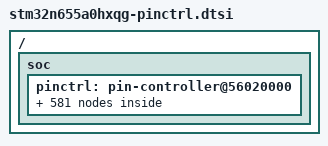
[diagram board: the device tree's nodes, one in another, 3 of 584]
/*
 * NOTE: Autogenerated file using genpinctrl.py
 *
 * SPDX-License-Identifier: Apache-2.0
 */

#include <zephyr/dt-bindings/pinctrl/stm32-pinctrl.h>

/ {
	soc {
		pinctrl: pin-controller@56020000 {

			/* ADC_IN / ADC_INN / ADC_INP */

			/omit-if-no-ref/ adc1_inn1_pa0: adc1_inn1_pa0 {
				pinmux = <STM32_PINMUX('A', 0, ANALOG)>;
			};

			/omit-if-no-ref/ adc1_inp0_pa0: adc1_inp0_pa0 {
				pinmux = <STM32_PINMUX('A', 0, ANALOG)>;
			};

			/omit-if-no-ref/ adc1_inp1_pa1: adc1_inp1_pa1 {
				pinmux = <STM32_PINMUX('A', 1, ANALOG)>;
			};

			/omit-if-no-ref/ adc1_inp14_pa2: adc1_inp14_pa2 {
				pinmux = <STM32_PINMUX('A', 2, ANALOG)>;
			};

			/omit-if-no-ref/ adc1_inp3_pa6: adc1_inp3_pa6 {
				pinmux = <STM32_PINMUX('A', 6, ANALOG)>;
			};

			/omit-if-no-ref/ adc1_inp5_pa8: adc1_inp5_pa8 {
				pinmux = <STM32_PINMUX('A', 8, ANALOG)>;
			};

			/omit-if-no-ref/ adc1_inp10_pa9: adc1_inp10_pa9 {
				pinmux = <STM32_PINMUX('A', 9, ANALOG)>;
			};

			/omit-if-no-ref/ adc1_inn10_pa10: adc1_inn10_pa10 {
				pinmux = <STM32_PINMUX('A', 10, ANALOG)>;
			};

			/omit-if-no-ref/ adc1_inp11_pa10: adc1_inp11_pa10 {
				pinmux = <STM32_PINMUX('A', 10, ANALOG)>;
			};

			/omit-if-no-ref/ adc1_inn11_pa11: adc1_inn11_pa11 {
				pinmux = <STM32_PINMUX('A', 11, ANALOG)>;
			};

			/omit-if-no-ref/ adc1_inp12_pa11: adc1_inp12_pa11 {
				pinmux = <STM32_PINMUX('A', 11, ANALOG)>;
			};

			/omit-if-no-ref/ adc1_inn12_pa12: adc1_inn12_pa12 {
				pinmux = <STM32_PINMUX('A', 12, ANALOG)>;
			};

			/omit-if-no-ref/ adc1_inp13_pa12: adc1_inp13_pa12 {
				pinmux = <STM32_PINMUX('A', 12, ANALOG)>;
			};

			/omit-if-no-ref/ adc1_inn4_pb10: adc1_inn4_pb10 {
				pinmux = <STM32_PINMUX('B', 10, ANALOG)>;
			};

			/omit-if-no-ref/ adc1_inp8_pb10: adc1_inp8_pb10 {
				pinmux = <STM32_PINMUX('B', 10, ANALOG)>;
			};

			/omit-if-no-ref/ adc1_inp4_pb11: adc1_inp4_pb11 {
				pinmux = <STM32_PINMUX('B', 11, ANALOG)>;
			};

			/omit-if-no-ref/ adc1_inp18_pf4: adc1_inp18_pf4 {
				pinmux = <STM32_PINMUX('F', 4, ANALOG)>;
			};

			/omit-if-no-ref/ adc1_inn5_pf7: adc1_inn5_pf7 {
				pinmux = <STM32_PINMUX('F', 7, ANALOG)>;
			};

			/omit-if-no-ref/ adc1_inp9_pf7: adc1_inp9_pf7 {
				pinmux = <STM32_PINMUX('F', 7, ANALOG)>;
			};

			/omit-if-no-ref/ adc1_inp2_pf11: adc1_inp2_pf11 {
				pinmux = <STM32_PINMUX('F', 11, ANALOG)>;
			};

			/omit-if-no-ref/ adc1_inn2_pf12: adc1_inn2_pf12 {
				pinmux = <STM32_PINMUX('F', 12, ANALOG)>;
			};

			/omit-if-no-ref/ adc1_inp6_pf12: adc1_inp6_pf12 {
				pinmux = <STM32_PINMUX('F', 12, ANALOG)>;
			};

			/omit-if-no-ref/ adc2_inn1_pa0: adc2_inn1_pa0 {
				pinmux = <STM32_PINMUX('A', 0, ANALOG)>;
			};

			/omit-if-no-ref/ adc2_inp0_pa0: adc2_inp0_pa0 {
				pinmux = <STM32_PINMUX('A', 0, ANALOG)>;
			};

			/omit-if-no-ref/ adc2_inp1_pa1: adc2_inp1_pa1 {
				pinmux = <STM32_PINMUX('A', 1, ANALOG)>;
			};

			/omit-if-no-ref/ adc2_inp14_pa2: adc2_inp14_pa2 {
				pinmux = <STM32_PINMUX('A', 2, ANALOG)>;
			};

			/omit-if-no-ref/ adc2_inp18_pa5: adc2_inp18_pa5 {
				pinmux = <STM32_PINMUX('A', 5, ANALOG)>;
			};

			/omit-if-no-ref/ adc2_inp3_pa6: adc2_inp3_pa6 {
				pinmux = <STM32_PINMUX('A', 6, ANALOG)>;
			};

			/omit-if-no-ref/ adc2_inp5_pa8: adc2_inp5_pa8 {
				pinmux = <STM32_PINMUX('A', 8, ANALOG)>;
			};

			/omit-if-no-ref/ adc2_inp10_pa9: adc2_inp10_pa9 {
				pinmux = <STM32_PINMUX('A', 9, ANALOG)>;
			};

			/omit-if-no-ref/ adc2_inn10_pa10: adc2_inn10_pa10 {
				pinmux = <STM32_PINMUX('A', 10, ANALOG)>;
			};

			/omit-if-no-ref/ adc2_inp11_pa10: adc2_inp11_pa10 {
				pinmux = <STM32_PINMUX('A', 10, ANALOG)>;
			};

			/omit-if-no-ref/ adc2_inn11_pa11: adc2_inn11_pa11 {
				pinmux = <STM32_PINMUX('A', 11, ANALOG)>;
			};

			/omit-if-no-ref/ adc2_inp12_pa11: adc2_inp12_pa11 {
				pinmux = <STM32_PINMUX('A', 11, ANALOG)>;
			};

			/omit-if-no-ref/ adc2_inn12_pa12: adc2_inn12_pa12 {
				pinmux = <STM32_PINMUX('A', 12, ANALOG)>;
			};

			/omit-if-no-ref/ adc2_inp13_pa12: adc2_inp13_pa12 {
				pinmux = <STM32_PINMUX('A', 12, ANALOG)>;
			};

			/omit-if-no-ref/ adc2_inn4_pb10: adc2_inn4_pb10 {
				pinmux = <STM32_PINMUX('B', 10, ANALOG)>;
			};

			/omit-if-no-ref/ adc2_inp8_pb10: adc2_inp8_pb10 {
				pinmux = <STM32_PINMUX('B', 10, ANALOG)>;
			};

			/omit-if-no-ref/ adc2_inp4_pb11: adc2_inp4_pb11 {
				pinmux = <STM32_PINMUX('B', 11, ANALOG)>;
			};

			/omit-if-no-ref/ adc2_inn5_pf7: adc2_inn5_pf7 {
				pinmux = <STM32_PINMUX('F', 7, ANALOG)>;
			};

			/omit-if-no-ref/ adc2_inp9_pf7: adc2_inp9_pf7 {
				pinmux = <STM32_PINMUX('F', 7, ANALOG)>;
			};

			/omit-if-no-ref/ adc2_inp2_pf13: adc2_inp2_pf13 {
				pinmux = <STM32_PINMUX('F', 13, ANALOG)>;
			};

			/omit-if-no-ref/ adc2_inn2_pf14: adc2_inn2_pf14 {
				pinmux = <STM32_PINMUX('F', 14, ANALOG)>;
			};

			/omit-if-no-ref/ adc2_inp6_pf14: adc2_inp6_pf14 {
				pinmux = <STM32_PINMUX('F', 14, ANALOG)>;
			};

			/* Analog */

			/omit-if-no-ref/ analog_pa0: analog_pa0 {
				pinmux = <STM32_PINMUX('A', 0, ANALOG)>;
			};

			/omit-if-no-ref/ analog_pa1: analog_pa1 {
				pinmux = <STM32_PINMUX('A', 1, ANALOG)>;
			};

			/omit-if-no-ref/ analog_pa2: analog_pa2 {
				pinmux = <STM32_PINMUX('A', 2, ANALOG)>;
			};

			/omit-if-no-ref/ analog_pa5: analog_pa5 {
				pinmux = <STM32_PINMUX('A', 5, ANALOG)>;
			};

			/omit-if-no-ref/ analog_pa6: analog_pa6 {
				pinmux = <STM32_PINMUX('A', 6, ANALOG)>;
			};

			/omit-if-no-ref/ analog_pa7: analog_pa7 {
				pinmux = <STM32_PINMUX('A', 7, ANALOG)>;
			};

			/omit-if-no-ref/ analog_pa8: analog_pa8 {
				pinmux = <STM32_PINMUX('A', 8, ANALOG)>;
			};

			/omit-if-no-ref/ analog_pa9: analog_pa9 {
				pinmux = <STM32_PINMUX('A', 9, ANALOG)>;
			};

			/omit-if-no-ref/ analog_pa10: analog_pa10 {
				pinmux = <STM32_PINMUX('A', 10, ANALOG)>;
			};

			/omit-if-no-ref/ analog_pa11: analog_pa11 {
				pinmux = <STM32_PINMUX('A', 11, ANALOG)>;
			};

			/omit-if-no-ref/ analog_pa12: analog_pa12 {
				pinmux = <STM32_PINMUX('A', 12, ANALOG)>;
			};

			/omit-if-no-ref/ analog_pa13: analog_pa13 {
				pinmux = <STM32_PINMUX('A', 13, ANALOG)>;
			};

			/omit-if-no-ref/ analog_pa14: analog_pa14 {
				pinmux = <STM32_PINMUX('A', 14, ANALOG)>;
			};

			/omit-if-no-ref/ analog_pa15: analog_pa15 {
				pinmux = <STM32_PINMUX('A', 15, ANALOG)>;
			};

			/omit-if-no-ref/ analog_pb4: analog_pb4 {
				pinmux = <STM32_PINMUX('B', 4, ANALOG)>;
			};

			/omit-if-no-ref/ analog_pb5: analog_pb5 {
				pinmux = <STM32_PINMUX('B', 5, ANALOG)>;
			};

			/omit-if-no-ref/ analog_pb6: analog_pb6 {
				pinmux = <STM32_PINMUX('B', 6, ANALOG)>;
			};

			/omit-if-no-ref/ analog_pb7: analog_pb7 {
				pinmux = <STM32_PINMUX('B', 7, ANALOG)>;
			};

			/omit-if-no-ref/ analog_pb8: analog_pb8 {
				pinmux = <STM32_PINMUX('B', 8, ANALOG)>;
			};

			/omit-if-no-ref/ analog_pb10: analog_pb10 {
				pinmux = <STM32_PINMUX('B', 10, ANALOG)>;
			};

			/omit-if-no-ref/ analog_pb11: analog_pb11 {
				pinmux = <STM32_PINMUX('B', 11, ANALOG)>;
			};

			/omit-if-no-ref/ analog_pb12: analog_pb12 {
				pinmux = <STM32_PINMUX('B', 12, ANALOG)>;
			};

			/omit-if-no-ref/ analog_pc0: analog_pc0 {
				pinmux = <STM32_PINMUX('C', 0, ANALOG)>;
			};

			/omit-if-no-ref/ analog_pc1: analog_pc1 {
				pinmux = <STM32_PINMUX('C', 1, ANALOG)>;
			};

			/omit-if-no-ref/ analog_pc2: analog_pc2 {
				pinmux = <STM32_PINMUX('C', 2, ANALOG)>;
			};

			/omit-if-no-ref/ analog_pc3: analog_pc3 {
				pinmux = <STM32_PINMUX('C', 3, ANALOG)>;
			};

			/omit-if-no-ref/ analog_pc4: analog_pc4 {
				pinmux = <STM32_PINMUX('C', 4, ANALOG)>;
			};

			/omit-if-no-ref/ analog_pc5: analog_pc5 {
				pinmux = <STM32_PINMUX('C', 5, ANALOG)>;
			};

			/omit-if-no-ref/ analog_pc6: analog_pc6 {
				pinmux = <STM32_PINMUX('C', 6, ANALOG)>;
			};

			/omit-if-no-ref/ analog_pc7: analog_pc7 {
				pinmux = <STM32_PINMUX('C', 7, ANALOG)>;
			};

			/omit-if-no-ref/ analog_pc8: analog_pc8 {
				pinmux = <STM32_PINMUX('C', 8, ANALOG)>;
			};

			/omit-if-no-ref/ analog_pc9: analog_pc9 {
				pinmux = <STM32_PINMUX('C', 9, ANALOG)>;
			};

			/omit-if-no-ref/ analog_pc10: analog_pc10 {
				pinmux = <STM32_PINMUX('C', 10, ANALOG)>;
			};

			/omit-if-no-ref/ analog_pc11: analog_pc11 {
				pinmux = <STM32_PINMUX('C', 11, ANALOG)>;
			};

			/omit-if-no-ref/ analog_pc12: analog_pc12 {
				pinmux = <STM32_PINMUX('C', 12, ANALOG)>;
			};

			/omit-if-no-ref/ analog_pc13: analog_pc13 {
				pinmux = <STM32_PINMUX('C', 13, ANALOG)>;
			};

			/omit-if-no-ref/ analog_pc14: analog_pc14 {
				pinmux = <STM32_PINMUX('C', 14, ANALOG)>;
			};

			/omit-if-no-ref/ analog_pc15: analog_pc15 {
				pinmux = <STM32_PINMUX('C', 15, ANALOG)>;
			};

			/omit-if-no-ref/ analog_pd8: analog_pd8 {
				pinmux = <STM32_PINMUX('D', 8, ANALOG)>;
			};

			/omit-if-no-ref/ analog_pd11: analog_pd11 {
				pinmux = <STM32_PINMUX('D', 11, ANALOG)>;
			};

			/omit-if-no-ref/ analog_pe0: analog_pe0 {
				pinmux = <STM32_PINMUX('E', 0, ANALOG)>;
			};

			/omit-if-no-ref/ analog_pe1: analog_pe1 {
				pinmux = <STM32_PINMUX('E', 1, ANALOG)>;
			};

			/omit-if-no-ref/ analog_pe3: analog_pe3 {
				pinmux = <STM32_PINMUX('E', 3, ANALOG)>;
			};

			/omit-if-no-ref/ analog_pe4: analog_pe4 {
				pinmux = <STM32_PINMUX('E', 4, ANALOG)>;
			};

			/omit-if-no-ref/ analog_pe5: analog_pe5 {
				pinmux = <STM32_PINMUX('E', 5, ANALOG)>;
			};

			/omit-if-no-ref/ analog_pe6: analog_pe6 {
				pinmux = <STM32_PINMUX('E', 6, ANALOG)>;
			};

			/omit-if-no-ref/ analog_pe7: analog_pe7 {
				pinmux = <STM32_PINMUX('E', 7, ANALOG)>;
			};

			/omit-if-no-ref/ analog_pe8: analog_pe8 {
				pinmux = <STM32_PINMUX('E', 8, ANALOG)>;
			};

			/omit-if-no-ref/ analog_pe9: analog_pe9 {
				pinmux = <STM32_PINMUX('E', 9, ANALOG)>;
			};

			/omit-if-no-ref/ analog_pe10: analog_pe10 {
				pinmux = <STM32_PINMUX('E', 10, ANALOG)>;
			};

			/omit-if-no-ref/ analog_pe13: analog_pe13 {
				pinmux = <STM32_PINMUX('E', 13, ANALOG)>;
			};

			/omit-if-no-ref/ analog_pf2: analog_pf2 {
				pinmux = <STM32_PINMUX('F', 2, ANALOG)>;
			};

			/omit-if-no-ref/ analog_pf4: analog_pf4 {
				pinmux = <STM32_PINMUX('F', 4, ANALOG)>;
			};

			/omit-if-no-ref/ analog_pf5: analog_pf5 {
				pinmux = <STM32_PINMUX('F', 5, ANALOG)>;
			};

			/omit-if-no-ref/ analog_pf7: analog_pf7 {
				pinmux = <STM32_PINMUX('F', 7, ANALOG)>;
			};

			/omit-if-no-ref/ analog_pf8: analog_pf8 {
				pinmux = <STM32_PINMUX('F', 8, ANALOG)>;
			};

			/omit-if-no-ref/ analog_pf10: analog_pf10 {
				pinmux = <STM32_PINMUX('F', 10, ANALOG)>;
			};

			/omit-if-no-ref/ analog_pf11: analog_pf11 {
				pinmux = <STM32_PINMUX('F', 11, ANALOG)>;
			};

			/omit-if-no-ref/ analog_pf12: analog_pf12 {
				pinmux = <STM32_PINMUX('F', 12, ANALOG)>;
			};

			/omit-if-no-ref/ analog_pf13: analog_pf13 {
				pinmux = <STM32_PINMUX('F', 13, ANALOG)>;
			};

			/omit-if-no-ref/ analog_pf14: analog_pf14 {
				pinmux = <STM32_PINMUX('F', 14, ANALOG)>;
			};

			/omit-if-no-ref/ analog_pf15: analog_pf15 {
				pinmux = <STM32_PINMUX('F', 15, ANALOG)>;
			};

			/omit-if-no-ref/ analog_pg2: analog_pg2 {
				pinmux = <STM32_PINMUX('G', 2, ANALOG)>;
			};

			/omit-if-no-ref/ analog_pg10: analog_pg10 {
				pinmux = <STM32_PINMUX('G', 10, ANALOG)>;
			};

			/omit-if-no-ref/ analog_pg13: analog_pg13 {
				pinmux = <STM32_PINMUX('G', 13, ANALOG)>;
			};

			/omit-if-no-ref/ analog_ph0: analog_ph0 {
				pinmux = <STM32_PINMUX('H', 0, ANALOG)>;
			};

			/omit-if-no-ref/ analog_ph1: analog_ph1 {
				pinmux = <STM32_PINMUX('H', 1, ANALOG)>;
			};

			/omit-if-no-ref/ analog_ph2: analog_ph2 {
				pinmux = <STM32_PINMUX('H', 2, ANALOG)>;
			};

			/omit-if-no-ref/ analog_ph9: analog_ph9 {
				pinmux = <STM32_PINMUX('H', 9, ANALOG)>;
			};

			/omit-if-no-ref/ analog_pn0: analog_pn0 {
				pinmux = <STM32_PINMUX('N', 0, ANALOG)>;
			};

			/omit-if-no-ref/ analog_pn1: analog_pn1 {
				pinmux = <STM32_PINMUX('N', 1, ANALOG)>;
			};

			/omit-if-no-ref/ analog_pn2: analog_pn2 {
				pinmux = <STM32_PINMUX('N', 2, ANALOG)>;
			};

			/omit-if-no-ref/ analog_pn3: analog_pn3 {
				pinmux = <STM32_PINMUX('N', 3, ANALOG)>;
			};

			/omit-if-no-ref/ analog_pn4: analog_pn4 {
				pinmux = <STM32_PINMUX('N', 4, ANALOG)>;
			};

			/omit-if-no-ref/ analog_pn5: analog_pn5 {
				pinmux = <STM32_PINMUX('N', 5, ANALOG)>;
			};

			/omit-if-no-ref/ analog_pn6: analog_pn6 {
				pinmux = <STM32_PINMUX('N', 6, ANALOG)>;
			};

			/omit-if-no-ref/ analog_pn7: analog_pn7 {
				pinmux = <STM32_PINMUX('N', 7, ANALOG)>;
			};

			/omit-if-no-ref/ analog_pn8: analog_pn8 {
				pinmux = <STM32_PINMUX('N', 8, ANALOG)>;
			};

			/omit-if-no-ref/ analog_pn9: analog_pn9 {
				pinmux = <STM32_PINMUX('N', 9, ANALOG)>;
			};

			/omit-if-no-ref/ analog_pn10: analog_pn10 {
				pinmux = <STM32_PINMUX('N', 10, ANALOG)>;
			};

			/omit-if-no-ref/ analog_pn11: analog_pn11 {
				pinmux = <STM32_PINMUX('N', 11, ANALOG)>;
			};

			/omit-if-no-ref/ analog_pn12: analog_pn12 {
				pinmux = <STM32_PINMUX('N', 12, ANALOG)>;
			};

			/omit-if-no-ref/ analog_po0: analog_po0 {
				pinmux = <STM32_PINMUX('O', 0, ANALOG)>;
			};

			/omit-if-no-ref/ analog_po1: analog_po1 {
				pinmux = <STM32_PINMUX('O', 1, ANALOG)>;
			};

			/omit-if-no-ref/ analog_po2: analog_po2 {
				pinmux = <STM32_PINMUX('O', 2, ANALOG)>;
			};

			/omit-if-no-ref/ analog_po3: analog_po3 {
				pinmux = <STM32_PINMUX('O', 3, ANALOG)>;
			};

			/omit-if-no-ref/ analog_po4: analog_po4 {
				pinmux = <STM32_PINMUX('O', 4, ANALOG)>;
			};

			/omit-if-no-ref/ analog_po5: analog_po5 {
				pinmux = <STM32_PINMUX('O', 5, ANALOG)>;
			};

			/omit-if-no-ref/ analog_pp0: analog_pp0 {
				pinmux = <STM32_PINMUX('P', 0, ANALOG)>;
			};

			/omit-if-no-ref/ analog_pp1: analog_pp1 {
				pinmux = <STM32_PINMUX('P', 1, ANALOG)>;
			};

			/omit-if-no-ref/ analog_pp2: analog_pp2 {
				pinmux = <STM32_PINMUX('P', 2, ANALOG)>;
			};

			/omit-if-no-ref/ analog_pp3: analog_pp3 {
				pinmux = <STM32_PINMUX('P', 3, ANALOG)>;
			};

			/omit-if-no-ref/ analog_pp4: analog_pp4 {
				pinmux = <STM32_PINMUX('P', 4, ANALOG)>;
			};

			/omit-if-no-ref/ analog_pp5: analog_pp5 {
				pinmux = <STM32_PINMUX('P', 5, ANALOG)>;
			};

			/omit-if-no-ref/ analog_pp6: analog_pp6 {
				pinmux = <STM32_PINMUX('P', 6, ANALOG)>;
			};

			/omit-if-no-ref/ analog_pp7: analog_pp7 {
				pinmux = <STM32_PINMUX('P', 7, ANALOG)>;
			};

			/omit-if-no-ref/ analog_pp8: analog_pp8 {
				pinmux = <STM32_PINMUX('P', 8, ANALOG)>;
			};

			/omit-if-no-ref/ analog_pp9: analog_pp9 {
				pinmux = <STM32_PINMUX('P', 9, ANALOG)>;
			};

			/omit-if-no-ref/ analog_pp10: analog_pp10 {
				pinmux = <STM32_PINMUX('P', 10, ANALOG)>;
			};

			/omit-if-no-ref/ analog_pp11: analog_pp11 {
				pinmux = <STM32_PINMUX('P', 11, ANALOG)>;
			};

			/omit-if-no-ref/ analog_pp12: analog_pp12 {
				pinmux = <STM32_PINMUX('P', 12, ANALOG)>;
			};

			/omit-if-no-ref/ analog_pp13: analog_pp13 {
				pinmux = <STM32_PINMUX('P', 13, ANALOG)>;
			};

			/omit-if-no-ref/ analog_pp14: analog_pp14 {
				pinmux = <STM32_PINMUX('P', 14, ANALOG)>;
			};

			/omit-if-no-ref/ analog_pp15: analog_pp15 {
				pinmux = <STM32_PINMUX('P', 15, ANALOG)>;
			};

			/* DCMI */

			/omit-if-no-ref/ dcmi_d0_pa1: dcmi_d0_pa1 {
				pinmux = <STM32_PINMUX('A', 1, AF9)>;
				slew-rate = "very-high-speed";
			};

			/omit-if-no-ref/ dcmi_d8_pa5: dcmi_d8_pa5 {
				pinmux = <STM32_PINMUX('A', 5, AF9)>;
				slew-rate = "very-high-speed";
			};

			/omit-if-no-ref/ dcmi_pixclk_pa6: dcmi_pixclk_pa6 {
				pinmux = <STM32_PINMUX('A', 6, AF9)>;
				slew-rate = "very-high-speed";
			};

			/omit-if-no-ref/ dcmi_d0_pa9: dcmi_d0_pa9 {
				pinmux = <STM32_PINMUX('A', 9, AF9)>;
				slew-rate = "very-high-speed";
			};

			/omit-if-no-ref/ dcmi_d1_pa10: dcmi_d1_pa10 {
				pinmux = <STM32_PINMUX('A', 10, AF9)>;
				slew-rate = "very-high-speed";
			};

			/omit-if-no-ref/ dcmi_vsync_pb4: dcmi_vsync_pb4 {
				pinmux = <STM32_PINMUX('B', 4, AF9)>;
				slew-rate = "very-high-speed";
			};

			/omit-if-no-ref/ dcmi_d10_pb5: dcmi_d10_pb5 {
				pinmux = <STM32_PINMUX('B', 5, AF9)>;
				slew-rate = "very-high-speed";
			};

			/omit-if-no-ref/ dcmi_d6_pb6: dcmi_d6_pb6 {
				pinmux = <STM32_PINMUX('B', 6, AF9)>;
				slew-rate = "very-high-speed";
			};

			/omit-if-no-ref/ dcmi_d7_pb7: dcmi_d7_pb7 {
				pinmux = <STM32_PINMUX('B', 7, AF9)>;
				slew-rate = "very-high-speed";
			};

			/omit-if-no-ref/ dcmi_vsync_pb8: dcmi_vsync_pb8 {
				pinmux = <STM32_PINMUX('B', 8, AF9)>;
				slew-rate = "very-high-speed";
			};

			/omit-if-no-ref/ dcmi_hsync_pc0: dcmi_hsync_pc0 {
				pinmux = <STM32_PINMUX('C', 0, AF9)>;
				slew-rate = "very-high-speed";
			};

			/omit-if-no-ref/ dcmi_d7_pc1: dcmi_d7_pc1 {
				pinmux = <STM32_PINMUX('C', 1, AF9)>;
				slew-rate = "very-high-speed";
			};

			/omit-if-no-ref/ dcmi_d13_pc2: dcmi_d13_pc2 {
				pinmux = <STM32_PINMUX('C', 2, AF9)>;
				slew-rate = "very-high-speed";
			};

			/omit-if-no-ref/ dcmi_d2_pc3: dcmi_d2_pc3 {
				pinmux = <STM32_PINMUX('C', 3, AF9)>;
				slew-rate = "very-high-speed";
			};

			/omit-if-no-ref/ dcmi_d2_pc5: dcmi_d2_pc5 {
				pinmux = <STM32_PINMUX('C', 5, AF9)>;
				slew-rate = "very-high-speed";
			};

			/omit-if-no-ref/ dcmi_d1_pc6: dcmi_d1_pc6 {
				pinmux = <STM32_PINMUX('C', 6, AF9)>;
				slew-rate = "very-high-speed";
			};

			/omit-if-no-ref/ dcmi_d1_pc7: dcmi_d1_pc7 {
				pinmux = <STM32_PINMUX('C', 7, AF9)>;
				slew-rate = "very-high-speed";
			};

			/omit-if-no-ref/ dcmi_d2_pc8: dcmi_d2_pc8 {
				pinmux = <STM32_PINMUX('C', 8, AF9)>;
				slew-rate = "very-high-speed";
			};

			/omit-if-no-ref/ dcmi_d3_pc9: dcmi_d3_pc9 {
				pinmux = <STM32_PINMUX('C', 9, AF9)>;
				slew-rate = "very-high-speed";
			};

			/omit-if-no-ref/ dcmi_d4_pc11: dcmi_d4_pc11 {
				pinmux = <STM32_PINMUX('C', 11, AF9)>;
				slew-rate = "very-high-speed";
			};

			/omit-if-no-ref/ dcmi_d9_pc12: dcmi_d9_pc12 {
				pinmux = <STM32_PINMUX('C', 12, AF9)>;
				slew-rate = "very-high-speed";
			};

			/omit-if-no-ref/ dcmi_d11_pd8: dcmi_d11_pd8 {
				pinmux = <STM32_PINMUX('D', 8, AF9)>;
				slew-rate = "very-high-speed";
			};

			/omit-if-no-ref/ dcmi_d2_pe0: dcmi_d2_pe0 {
				pinmux = <STM32_PINMUX('E', 0, AF9)>;
				slew-rate = "very-high-speed";
			};

			/omit-if-no-ref/ dcmi_d8_pe1: dcmi_d8_pe1 {
				pinmux = <STM32_PINMUX('E', 1, AF9)>;
				slew-rate = "very-high-speed";
			};

			/omit-if-no-ref/ dcmi_d5_pe4: dcmi_d5_pe4 {
				pinmux = <STM32_PINMUX('E', 4, AF9)>;
				slew-rate = "very-high-speed";
			};

			/omit-if-no-ref/ dcmi_d5_pe5: dcmi_d5_pe5 {
				pinmux = <STM32_PINMUX('E', 5, AF9)>;
				slew-rate = "very-high-speed";
			};

			/omit-if-no-ref/ dcmi_d1_pe6: dcmi_d1_pe6 {
				pinmux = <STM32_PINMUX('E', 6, AF10)>;
				slew-rate = "very-high-speed";
			};

			/omit-if-no-ref/ dcmi_vsync_pe6: dcmi_vsync_pe6 {
				pinmux = <STM32_PINMUX('E', 6, AF9)>;
				slew-rate = "very-high-speed";
			};

			/omit-if-no-ref/ dcmi_d4_pe8: dcmi_d4_pe8 {
				pinmux = <STM32_PINMUX('E', 8, AF9)>;
				slew-rate = "very-high-speed";
			};

			/omit-if-no-ref/ dcmi_d3_pe10: dcmi_d3_pe10 {
				pinmux = <STM32_PINMUX('E', 10, AF9)>;
				slew-rate = "very-high-speed";
			};

			/omit-if-no-ref/ dcmi_hsync_pf4: dcmi_hsync_pf4 {
				pinmux = <STM32_PINMUX('F', 4, AF9)>;
				slew-rate = "very-high-speed";
			};

			/omit-if-no-ref/ dcmi_d6_pf5: dcmi_d6_pf5 {
				pinmux = <STM32_PINMUX('F', 5, AF9)>;
				slew-rate = "very-high-speed";
			};

			/omit-if-no-ref/ dcmi_d11_pf10: dcmi_d11_pf10 {
				pinmux = <STM32_PINMUX('F', 10, AF9)>;
				slew-rate = "very-high-speed";
			};

			/omit-if-no-ref/ dcmi_d13_pf12: dcmi_d13_pf12 {
				pinmux = <STM32_PINMUX('F', 12, AF9)>;
				slew-rate = "very-high-speed";
			};

			/omit-if-no-ref/ dcmi_d10_pf13: dcmi_d10_pf13 {
				pinmux = <STM32_PINMUX('F', 13, AF9)>;
				slew-rate = "very-high-speed";
			};

			/omit-if-no-ref/ dcmi_d6_pg2: dcmi_d6_pg2 {
				pinmux = <STM32_PINMUX('G', 2, AF9)>;
				slew-rate = "very-high-speed";
			};

			/omit-if-no-ref/ dcmi_d2_pg10: dcmi_d2_pg10 {
				pinmux = <STM32_PINMUX('G', 10, AF9)>;
				slew-rate = "very-high-speed";
			};

			/omit-if-no-ref/ dcmi_d12_pg13: dcmi_d12_pg13 {
				pinmux = <STM32_PINMUX('G', 13, AF9)>;
				slew-rate = "very-high-speed";
			};

			/omit-if-no-ref/ dcmi_d11_ph2: dcmi_d11_ph2 {
				pinmux = <STM32_PINMUX('H', 2, AF9)>;
				slew-rate = "very-high-speed";
			};

			/omit-if-no-ref/ dcmi_d6_ph9: dcmi_d6_ph9 {
				pinmux = <STM32_PINMUX('H', 9, AF9)>;
				slew-rate = "very-high-speed";
			};

			/omit-if-no-ref/ dcmi_d5_pn9: dcmi_d5_pn9 {
				pinmux = <STM32_PINMUX('N', 9, AF10)>;
				slew-rate = "very-high-speed";
			};

			/* DCMIPP */

			/omit-if-no-ref/ dcmipp_d0_pa1: dcmipp_d0_pa1 {
				pinmux = <STM32_PINMUX('A', 1, AF9)>;
				slew-rate = "very-high-speed";
			};

			/omit-if-no-ref/ dcmipp_d8_pa5: dcmipp_d8_pa5 {
				pinmux = <STM32_PINMUX('A', 5, AF9)>;
				slew-rate = "very-high-speed";
			};

			/omit-if-no-ref/ dcmipp_pixclk_pa6: dcmipp_pixclk_pa6 {
				pinmux = <STM32_PINMUX('A', 6, AF9)>;
				slew-rate = "very-high-speed";
			};

			/omit-if-no-ref/ dcmipp_d0_pa9: dcmipp_d0_pa9 {
				pinmux = <STM32_PINMUX('A', 9, AF9)>;
				slew-rate = "very-high-speed";
			};

			/omit-if-no-ref/ dcmipp_d1_pa10: dcmipp_d1_pa10 {
				pinmux = <STM32_PINMUX('A', 10, AF9)>;
				slew-rate = "very-high-speed";
			};

			/omit-if-no-ref/ dcmipp_vsync_pb4: dcmipp_vsync_pb4 {
				pinmux = <STM32_PINMUX('B', 4, AF9)>;
				slew-rate = "very-high-speed";
			};

			/omit-if-no-ref/ dcmipp_d10_pb5: dcmipp_d10_pb5 {
				pinmux = <STM32_PINMUX('B', 5, AF9)>;
				slew-rate = "very-high-speed";
			};

			/omit-if-no-ref/ dcmipp_d6_pb6: dcmipp_d6_pb6 {
				pinmux = <STM32_PINMUX('B', 6, AF9)>;
				slew-rate = "very-high-speed";
			};

			/omit-if-no-ref/ dcmipp_d7_pb7: dcmipp_d7_pb7 {
				pinmux = <STM32_PINMUX('B', 7, AF9)>;
				slew-rate = "very-high-speed";
			};

			/omit-if-no-ref/ dcmipp_vsync_pb8: dcmipp_vsync_pb8 {
				pinmux = <STM32_PINMUX('B', 8, AF9)>;
				slew-rate = "very-high-speed";
			};

			/omit-if-no-ref/ dcmipp_hsync_pc0: dcmipp_hsync_pc0 {
				pinmux = <STM32_PINMUX('C', 0, AF9)>;
				slew-rate = "very-high-speed";
			};

			/omit-if-no-ref/ dcmipp_d7_pc1: dcmipp_d7_pc1 {
				pinmux = <STM32_PINMUX('C', 1, AF9)>;
				slew-rate = "very-high-speed";
			};

			/omit-if-no-ref/ dcmipp_d13_pc2: dcmipp_d13_pc2 {
				pinmux = <STM32_PINMUX('C', 2, AF9)>;
				slew-rate = "very-high-speed";
			};

			/omit-if-no-ref/ dcmipp_d2_pc3: dcmipp_d2_pc3 {
				pinmux = <STM32_PINMUX('C', 3, AF9)>;
				slew-rate = "very-high-speed";
			};

			/omit-if-no-ref/ dcmipp_d2_pc5: dcmipp_d2_pc5 {
				pinmux = <STM32_PINMUX('C', 5, AF9)>;
				slew-rate = "very-high-speed";
			};

			/omit-if-no-ref/ dcmipp_d1_pc6: dcmipp_d1_pc6 {
				pinmux = <STM32_PINMUX('C', 6, AF9)>;
				slew-rate = "very-high-speed";
			};

			/omit-if-no-ref/ dcmipp_d1_pc7: dcmipp_d1_pc7 {
				pinmux = <STM32_PINMUX('C', 7, AF9)>;
				slew-rate = "very-high-speed";
			};

			/omit-if-no-ref/ dcmipp_d2_pc8: dcmipp_d2_pc8 {
				pinmux = <STM32_PINMUX('C', 8, AF9)>;
				slew-rate = "very-high-speed";
			};

			/omit-if-no-ref/ dcmipp_d3_pc9: dcmipp_d3_pc9 {
				pinmux = <STM32_PINMUX('C', 9, AF9)>;
				slew-rate = "very-high-speed";
			};

			/omit-if-no-ref/ dcmipp_d14_pc10: dcmipp_d14_pc10 {
				pinmux = <STM32_PINMUX('C', 10, AF9)>;
				slew-rate = "very-high-speed";
			};

			/omit-if-no-ref/ dcmipp_d4_pc11: dcmipp_d4_pc11 {
				pinmux = <STM32_PINMUX('C', 11, AF9)>;
				slew-rate = "very-high-speed";
			};

			/omit-if-no-ref/ dcmipp_d9_pc12: dcmipp_d9_pc12 {
				pinmux = <STM32_PINMUX('C', 12, AF9)>;
				slew-rate = "very-high-speed";
			};

			/omit-if-no-ref/ dcmipp_d11_pd8: dcmipp_d11_pd8 {
				pinmux = <STM32_PINMUX('D', 8, AF9)>;
				slew-rate = "very-high-speed";
			};

			/omit-if-no-ref/ dcmipp_d15_pd11: dcmipp_d15_pd11 {
				pinmux = <STM32_PINMUX('D', 11, AF9)>;
				slew-rate = "very-high-speed";
			};

			/omit-if-no-ref/ dcmipp_d2_pe0: dcmipp_d2_pe0 {
				pinmux = <STM32_PINMUX('E', 0, AF9)>;
				slew-rate = "very-high-speed";
			};

			/omit-if-no-ref/ dcmipp_d8_pe1: dcmipp_d8_pe1 {
				pinmux = <STM32_PINMUX('E', 1, AF9)>;
				slew-rate = "very-high-speed";
			};

			/omit-if-no-ref/ dcmipp_d5_pe4: dcmipp_d5_pe4 {
				pinmux = <STM32_PINMUX('E', 4, AF9)>;
				slew-rate = "very-high-speed";
			};

			/omit-if-no-ref/ dcmipp_d5_pe5: dcmipp_d5_pe5 {
				pinmux = <STM32_PINMUX('E', 5, AF9)>;
				slew-rate = "very-high-speed";
			};

			/omit-if-no-ref/ dcmipp_d1_pe6: dcmipp_d1_pe6 {
				pinmux = <STM32_PINMUX('E', 6, AF10)>;
				slew-rate = "very-high-speed";
			};

			/omit-if-no-ref/ dcmipp_vsync_pe6: dcmipp_vsync_pe6 {
				pinmux = <STM32_PINMUX('E', 6, AF9)>;
				slew-rate = "very-high-speed";
			};

			/omit-if-no-ref/ dcmipp_d4_pe8: dcmipp_d4_pe8 {
				pinmux = <STM32_PINMUX('E', 8, AF9)>;
				slew-rate = "very-high-speed";
			};

			/omit-if-no-ref/ dcmipp_d3_pe10: dcmipp_d3_pe10 {
				pinmux = <STM32_PINMUX('E', 10, AF9)>;
				slew-rate = "very-high-speed";
			};

			/omit-if-no-ref/ dcmipp_hsync_pf4: dcmipp_hsync_pf4 {
				pinmux = <STM32_PINMUX('F', 4, AF9)>;
				slew-rate = "very-high-speed";
			};

			/omit-if-no-ref/ dcmipp_d6_pf5: dcmipp_d6_pf5 {
				pinmux = <STM32_PINMUX('F', 5, AF9)>;
				slew-rate = "very-high-speed";
			};

			/omit-if-no-ref/ dcmipp_d11_pf10: dcmipp_d11_pf10 {
				pinmux = <STM32_PINMUX('F', 10, AF9)>;
				slew-rate = "very-high-speed";
			};

			/omit-if-no-ref/ dcmipp_d15_pf10: dcmipp_d15_pf10 {
				pinmux = <STM32_PINMUX('F', 10, AF10)>;
				slew-rate = "very-high-speed";
			};

			/omit-if-no-ref/ dcmipp_d15_pf11: dcmipp_d15_pf11 {
				pinmux = <STM32_PINMUX('F', 11, AF9)>;
				slew-rate = "very-high-speed";
			};

			/omit-if-no-ref/ dcmipp_d13_pf12: dcmipp_d13_pf12 {
				pinmux = <STM32_PINMUX('F', 12, AF9)>;
				slew-rate = "very-high-speed";
			};

			/omit-if-no-ref/ dcmipp_d10_pf13: dcmipp_d10_pf13 {
				pinmux = <STM32_PINMUX('F', 13, AF9)>;
				slew-rate = "very-high-speed";
			};

			/omit-if-no-ref/ dcmipp_d6_pg2: dcmipp_d6_pg2 {
				pinmux = <STM32_PINMUX('G', 2, AF9)>;
				slew-rate = "very-high-speed";
			};

			/omit-if-no-ref/ dcmipp_d2_pg10: dcmipp_d2_pg10 {
				pinmux = <STM32_PINMUX('G', 10, AF9)>;
				slew-rate = "very-high-speed";
			};

			/omit-if-no-ref/ dcmipp_d12_pg13: dcmipp_d12_pg13 {
				pinmux = <STM32_PINMUX('G', 13, AF9)>;
				slew-rate = "very-high-speed";
			};

			/omit-if-no-ref/ dcmipp_d11_ph2: dcmipp_d11_ph2 {
				pinmux = <STM32_PINMUX('H', 2, AF9)>;
				slew-rate = "very-high-speed";
			};

			/omit-if-no-ref/ dcmipp_d6_ph9: dcmipp_d6_ph9 {
				pinmux = <STM32_PINMUX('H', 9, AF9)>;
				slew-rate = "very-high-speed";
			};

			/omit-if-no-ref/ dcmipp_d5_pn9: dcmipp_d5_pn9 {
				pinmux = <STM32_PINMUX('N', 9, AF10)>;
				slew-rate = "very-high-speed";
			};

			/* FDCAN_RX */

			/omit-if-no-ref/ fdcan1_rx_pa11: fdcan1_rx_pa11 {
				pinmux = <STM32_PINMUX('A', 11, AF6)>;
			};

			/omit-if-no-ref/ fdcan1_rx_ph9: fdcan1_rx_ph9 {
				pinmux = <STM32_PINMUX('H', 9, AF6)>;
			};

			/omit-if-no-ref/ fdcan2_rx_pb5: fdcan2_rx_pb5 {
				pinmux = <STM32_PINMUX('B', 5, AF6)>;
			};

			/omit-if-no-ref/ fdcan2_rx_pb12: fdcan2_rx_pb12 {
				pinmux = <STM32_PINMUX('B', 12, AF6)>;
			};

			/* FDCAN_TX */

			/omit-if-no-ref/ fdcan1_tx_pa12: fdcan1_tx_pa12 {
				pinmux = <STM32_PINMUX('A', 12, AF6)>;
			};

			/omit-if-no-ref/ fdcan1_tx_pc1: fdcan1_tx_pc1 {
				pinmux = <STM32_PINMUX('C', 1, AF6)>;
			};

			/omit-if-no-ref/ fdcan1_tx_ph2: fdcan1_tx_ph2 {
				pinmux = <STM32_PINMUX('H', 2, AF6)>;
			};

			/omit-if-no-ref/ fdcan2_tx_pe5: fdcan2_tx_pe5 {
				pinmux = <STM32_PINMUX('E', 5, AF6)>;
			};

			/omit-if-no-ref/ fdcan2_tx_pg10: fdcan2_tx_pg10 {
				pinmux = <STM32_PINMUX('G', 10, AF6)>;
			};

			/* I2C_SCL */

			/omit-if-no-ref/ i2c1_scl_pe5: i2c1_scl_pe5 {
				pinmux = <STM32_PINMUX('E', 5, AF4)>;
				bias-pull-up;
				drive-open-drain;
			};

			/omit-if-no-ref/ i2c1_scl_ph9: i2c1_scl_ph9 {
				pinmux = <STM32_PINMUX('H', 9, AF4)>;
				bias-pull-up;
				drive-open-drain;
			};

			/omit-if-no-ref/ i2c2_scl_pb10: i2c2_scl_pb10 {
				pinmux = <STM32_PINMUX('B', 10, AF4)>;
				bias-pull-up;
				drive-open-drain;
			};

			/omit-if-no-ref/ i2c3_scl_pa8: i2c3_scl_pa8 {
				pinmux = <STM32_PINMUX('A', 8, AF4)>;
				bias-pull-up;
				drive-open-drain;
			};

			/omit-if-no-ref/ i2c4_scl_pc10: i2c4_scl_pc10 {
				pinmux = <STM32_PINMUX('C', 10, AF4)>;
				bias-pull-up;
				drive-open-drain;
			};

			/omit-if-no-ref/ i2c4_scl_pe13: i2c4_scl_pe13 {
				pinmux = <STM32_PINMUX('E', 13, AF4)>;
				bias-pull-up;
				drive-open-drain;
			};

			/* I2C_SDA */

			/omit-if-no-ref/ i2c1_sda_pc1: i2c1_sda_pc1 {
				pinmux = <STM32_PINMUX('C', 1, AF4)>;
				bias-pull-up;
				drive-open-drain;
			};

			/omit-if-no-ref/ i2c1_sda_pe6: i2c1_sda_pe6 {
				pinmux = <STM32_PINMUX('E', 6, AF4)>;
				bias-pull-up;
				drive-open-drain;
			};

			/omit-if-no-ref/ i2c2_sda_pb11: i2c2_sda_pb11 {
				pinmux = <STM32_PINMUX('B', 11, AF4)>;
				bias-pull-up;
				drive-open-drain;
			};

			/omit-if-no-ref/ i2c3_sda_pa9: i2c3_sda_pa9 {
				pinmux = <STM32_PINMUX('A', 9, AF4)>;
				bias-pull-up;
				drive-open-drain;
			};

			/omit-if-no-ref/ i2c3_sda_pc9: i2c3_sda_pc9 {
				pinmux = <STM32_PINMUX('C', 9, AF4)>;
				bias-pull-up;
				drive-open-drain;
			};

			/omit-if-no-ref/ i2c4_sda_pc11: i2c4_sda_pc11 {
				pinmux = <STM32_PINMUX('C', 11, AF4)>;
				bias-pull-up;
				drive-open-drain;
			};

			/omit-if-no-ref/ i2c4_sda_pd11: i2c4_sda_pd11 {
				pinmux = <STM32_PINMUX('D', 11, AF4)>;
				bias-pull-up;
				drive-open-drain;
			};

			/* I2C_SMBA */

			/omit-if-no-ref/ i2c1_smba_pb5: i2c1_smba_pb5 {
				pinmux = <STM32_PINMUX('B', 5, AF4)>;
				bias-pull-up;
			};

			/omit-if-no-ref/ i2c2_smba_pb12: i2c2_smba_pb12 {
				pinmux = <STM32_PINMUX('B', 12, AF4)>;
				bias-pull-up;
			};

			/omit-if-no-ref/ i2c3_smba_pc8: i2c3_smba_pc8 {
				pinmux = <STM32_PINMUX('C', 8, AF4)>;
				bias-pull-up;
			};

			/* I2S_CK */

			/omit-if-no-ref/ i2s3_ck_pc0: i2s3_ck_pc0 {
				pinmux = <STM32_PINMUX('C', 0, AF6)>;
				slew-rate = "very-high-speed";
			};

			/omit-if-no-ref/ i2s3_ck_pc10: i2s3_ck_pc10 {
				pinmux = <STM32_PINMUX('C', 10, AF6)>;
				slew-rate = "very-high-speed";
			};

			/* I2S_MCK */

			/omit-if-no-ref/ i2s3_mck_pc7: i2s3_mck_pc7 {
				pinmux = <STM32_PINMUX('C', 7, AF6)>;
				slew-rate = "very-high-speed";
			};

			/* I2S_WS */

			/omit-if-no-ref/ i2s3_ws_pa15: i2s3_ws_pa15 {
				pinmux = <STM32_PINMUX('A', 15, AF6)>;
			};

			/omit-if-no-ref/ i2s3_ws_pf4: i2s3_ws_pf4 {
				pinmux = <STM32_PINMUX('F', 4, AF6)>;
			};

			/* I3C_SCL */

			/omit-if-no-ref/ i3c1_scl_pa5: i3c1_scl_pa5 {
				pinmux = <STM32_PINMUX('A', 5, AF4)>;
				slew-rate = "very-high-speed";
			};

			/omit-if-no-ref/ i3c1_scl_pe5: i3c1_scl_pe5 {
				pinmux = <STM32_PINMUX('E', 5, AF5)>;
				slew-rate = "very-high-speed";
			};

			/omit-if-no-ref/ i3c1_scl_ph9: i3c1_scl_ph9 {
				pinmux = <STM32_PINMUX('H', 9, AF7)>;
				slew-rate = "very-high-speed";
			};

			/omit-if-no-ref/ i3c2_scl_pa8: i3c2_scl_pa8 {
				pinmux = <STM32_PINMUX('A', 8, AF2)>;
				slew-rate = "very-high-speed";
			};

			/omit-if-no-ref/ i3c2_scl_pb10: i3c2_scl_pb10 {
				pinmux = <STM32_PINMUX('B', 10, AF2)>;
				slew-rate = "very-high-speed";
			};

			/omit-if-no-ref/ i3c2_scl_pc10: i3c2_scl_pc10 {
				pinmux = <STM32_PINMUX('C', 10, AF2)>;
				slew-rate = "very-high-speed";
			};

			/* I3C_SDA */

			/omit-if-no-ref/ i3c1_sda_pa6: i3c1_sda_pa6 {
				pinmux = <STM32_PINMUX('A', 6, AF4)>;
				slew-rate = "very-high-speed";
			};

			/omit-if-no-ref/ i3c1_sda_pc1: i3c1_sda_pc1 {
				pinmux = <STM32_PINMUX('C', 1, AF7)>;
				slew-rate = "very-high-speed";
			};

			/omit-if-no-ref/ i3c1_sda_pe6: i3c1_sda_pe6 {
				pinmux = <STM32_PINMUX('E', 6, AF5)>;
				slew-rate = "very-high-speed";
			};

			/omit-if-no-ref/ i3c2_sda_pa9: i3c2_sda_pa9 {
				pinmux = <STM32_PINMUX('A', 9, AF2)>;
				slew-rate = "very-high-speed";
			};

			/omit-if-no-ref/ i3c2_sda_pb11: i3c2_sda_pb11 {
				pinmux = <STM32_PINMUX('B', 11, AF2)>;
				slew-rate = "very-high-speed";
			};

			/omit-if-no-ref/ i3c2_sda_pc11: i3c2_sda_pc11 {
				pinmux = <STM32_PINMUX('C', 11, AF2)>;
				slew-rate = "very-high-speed";
			};

			/* JTAG PORT */

			/omit-if-no-ref/ debug_jtms_swdio_pa13: debug_jtms_swdio_pa13 {
				pinmux = <STM32_PINMUX('A', 13, AF0)>;
			};

			/omit-if-no-ref/ debug_jtck_swclk_pa14: debug_jtck_swclk_pa14 {
				pinmux = <STM32_PINMUX('A', 14, AF0)>;
			};

			/omit-if-no-ref/ debug_jtdi_pa15: debug_jtdi_pa15 {
				pinmux = <STM32_PINMUX('A', 15, AF0)>;
			};

			/omit-if-no-ref/ debug_njtrst_pb4: debug_njtrst_pb4 {
				pinmux = <STM32_PINMUX('B', 4, AF0)>;
			};

			/omit-if-no-ref/ debug_jtdo_swo_pb5: debug_jtdo_swo_pb5 {
				pinmux = <STM32_PINMUX('B', 5, AF0)>;
			};

			/* LPTIM */

			/omit-if-no-ref/ lptim2_in1_pb10: lptim2_in1_pb10 {
				pinmux = <STM32_PINMUX('B', 10, AF3)>;
			};

			/omit-if-no-ref/ lptim2_etr_pb11: lptim2_etr_pb11 {
				pinmux = <STM32_PINMUX('B', 11, AF3)>;
			};

			/omit-if-no-ref/ lptim2_in2_pb12: lptim2_in2_pb12 {
				pinmux = <STM32_PINMUX('B', 12, AF3)>;
			};

			/omit-if-no-ref/ lptim2_ch2_pc4: lptim2_ch2_pc4 {
				pinmux = <STM32_PINMUX('C', 4, AF3)>;
			};

			/omit-if-no-ref/ lptim2_etr_pe0: lptim2_etr_pe0 {
				pinmux = <STM32_PINMUX('E', 0, AF3)>;
			};

			/omit-if-no-ref/ lptim2_ch2_pe1: lptim2_ch2_pe1 {
				pinmux = <STM32_PINMUX('E', 1, AF3)>;
			};

			/omit-if-no-ref/ lptim2_in2_pf5: lptim2_in2_pf5 {
				pinmux = <STM32_PINMUX('F', 5, AF3)>;
			};

			/omit-if-no-ref/ lptim2_ch1_pg10: lptim2_ch1_pg10 {
				pinmux = <STM32_PINMUX('G', 10, AF3)>;
			};

			/omit-if-no-ref/ lptim2_in1_pg13: lptim2_in1_pg13 {
				pinmux = <STM32_PINMUX('G', 13, AF3)>;
			};

			/omit-if-no-ref/ lptim4_etr_pb4: lptim4_etr_pb4 {
				pinmux = <STM32_PINMUX('B', 4, AF3)>;
			};

			/omit-if-no-ref/ lptim4_out_pb5: lptim4_out_pb5 {
				pinmux = <STM32_PINMUX('B', 5, AF3)>;
			};

			/omit-if-no-ref/ lptim4_in1_pc0: lptim4_in1_pc0 {
				pinmux = <STM32_PINMUX('C', 0, AF3)>;
			};

			/* LTDC */

			/omit-if-no-ref/ ltdc_g3_pa0: ltdc_g3_pa0 {
				pinmux = <STM32_PINMUX('A', 0, AF14)>;
			};

			/omit-if-no-ref/ ltdc_g2_pa1: ltdc_g2_pa1 {
				pinmux = <STM32_PINMUX('A', 1, AF14)>;
			};

			/omit-if-no-ref/ ltdc_b7_pa2: ltdc_b7_pa2 {
				pinmux = <STM32_PINMUX('A', 2, AF14)>;
			};

			/omit-if-no-ref/ ltdc_clk_pa5: ltdc_clk_pa5 {
				pinmux = <STM32_PINMUX('A', 5, AF14)>;
			};

			/omit-if-no-ref/ ltdc_b7_pa6: ltdc_b7_pa6 {
				pinmux = <STM32_PINMUX('A', 6, AF12)>;
			};

			/omit-if-no-ref/ ltdc_hsync_pa6: ltdc_hsync_pa6 {
				pinmux = <STM32_PINMUX('A', 6, AF14)>;
			};

			/omit-if-no-ref/ ltdc_b1_pa7: ltdc_b1_pa7 {
				pinmux = <STM32_PINMUX('A', 7, AF14)>;
			};

			/omit-if-no-ref/ ltdc_r4_pa7: ltdc_r4_pa7 {
				pinmux = <STM32_PINMUX('A', 7, AF10)>;
			};

			/omit-if-no-ref/ ltdc_b6_pa8: ltdc_b6_pa8 {
				pinmux = <STM32_PINMUX('A', 8, AF14)>;
			};

			/omit-if-no-ref/ ltdc_b5_pa9: ltdc_b5_pa9 {
				pinmux = <STM32_PINMUX('A', 9, AF14)>;
			};

			/omit-if-no-ref/ ltdc_b4_pa10: ltdc_b4_pa10 {
				pinmux = <STM32_PINMUX('A', 10, AF14)>;
			};

			/omit-if-no-ref/ ltdc_b3_pa11: ltdc_b3_pa11 {
				pinmux = <STM32_PINMUX('A', 11, AF14)>;
			};

			/omit-if-no-ref/ ltdc_b2_pa12: ltdc_b2_pa12 {
				pinmux = <STM32_PINMUX('A', 12, AF14)>;
			};

			/omit-if-no-ref/ ltdc_r5_pa15: ltdc_r5_pa15 {
				pinmux = <STM32_PINMUX('A', 15, AF14)>;
			};

			/omit-if-no-ref/ ltdc_r3_pb4: ltdc_r3_pb4 {
				pinmux = <STM32_PINMUX('B', 4, AF14)>;
			};

			/omit-if-no-ref/ ltdc_r2_pb5: ltdc_r2_pb5 {
				pinmux = <STM32_PINMUX('B', 5, AF14)>;
			};

			/omit-if-no-ref/ ltdc_g7_pb10: ltdc_g7_pb10 {
				pinmux = <STM32_PINMUX('B', 10, AF14)>;
			};

			/omit-if-no-ref/ ltdc_g6_pb11: ltdc_g6_pb11 {
				pinmux = <STM32_PINMUX('B', 11, AF14)>;
			};

			/omit-if-no-ref/ ltdc_g5_pb12: ltdc_g5_pb12 {
				pinmux = <STM32_PINMUX('B', 12, AF14)>;
			};

			/omit-if-no-ref/ ltdc_r4_pc0: ltdc_r4_pc0 {
				pinmux = <STM32_PINMUX('C', 0, AF14)>;
			};

			/omit-if-no-ref/ ltdc_de_pc4: ltdc_de_pc4 {
				pinmux = <STM32_PINMUX('C', 4, AF14)>;
			};

			/omit-if-no-ref/ ltdc_vsync_pc4: ltdc_vsync_pc4 {
				pinmux = <STM32_PINMUX('C', 4, AF10)>;
			};

			/omit-if-no-ref/ ltdc_b0_pc8: ltdc_b0_pc8 {
				pinmux = <STM32_PINMUX('C', 8, AF14)>;
			};

			/omit-if-no-ref/ ltdc_b3_pc9: ltdc_b3_pc9 {
				pinmux = <STM32_PINMUX('C', 9, AF14)>;
			};

			/omit-if-no-ref/ ltdc_r7_pd8: ltdc_r7_pd8 {
				pinmux = <STM32_PINMUX('D', 8, AF14)>;
			};

			/omit-if-no-ref/ ltdc_g1_pe4: ltdc_g1_pe4 {
				pinmux = <STM32_PINMUX('E', 4, AF14)>;
			};

			/omit-if-no-ref/ ltdc_b1_pf2: ltdc_b1_pf2 {
				pinmux = <STM32_PINMUX('F', 2, AF14)>;
			};

			/omit-if-no-ref/ ltdc_r3_pf4: ltdc_r3_pf4 {
				pinmux = <STM32_PINMUX('F', 4, AF14)>;
			};

			/omit-if-no-ref/ ltdc_g0_pf5: ltdc_g0_pf5 {
				pinmux = <STM32_PINMUX('F', 5, AF14)>;
			};

			/omit-if-no-ref/ ltdc_vsync_pf7: ltdc_vsync_pf7 {
				pinmux = <STM32_PINMUX('F', 7, AF14)>;
			};

			/omit-if-no-ref/ ltdc_r6_pf8: ltdc_r6_pf8 {
				pinmux = <STM32_PINMUX('F', 8, AF14)>;
			};

			/omit-if-no-ref/ ltdc_r1_pf10: ltdc_r1_pf10 {
				pinmux = <STM32_PINMUX('F', 10, AF14)>;
			};

			/omit-if-no-ref/ ltdc_b0_pf11: ltdc_b0_pf11 {
				pinmux = <STM32_PINMUX('F', 11, AF14)>;
			};

			/omit-if-no-ref/ ltdc_g0_pf14: ltdc_g0_pf14 {
				pinmux = <STM32_PINMUX('F', 14, AF14)>;
			};

			/omit-if-no-ref/ ltdc_g1_pf15: ltdc_g1_pf15 {
				pinmux = <STM32_PINMUX('F', 15, AF14)>;
			};

			/omit-if-no-ref/ ltdc_r0_pg2: ltdc_r0_pg2 {
				pinmux = <STM32_PINMUX('G', 2, AF14)>;
			};

			/omit-if-no-ref/ ltdc_g4_pg10: ltdc_g4_pg10 {
				pinmux = <STM32_PINMUX('G', 10, AF14)>;
			};

			/omit-if-no-ref/ ltdc_de_pg13: ltdc_de_pg13 {
				pinmux = <STM32_PINMUX('G', 13, AF14)>;
			};

			/omit-if-no-ref/ ltdc_b4_pn10: ltdc_b4_pn10 {
				pinmux = <STM32_PINMUX('N', 10, AF14)>;
			};

			/omit-if-no-ref/ ltdc_b6_pn11: ltdc_b6_pn11 {
				pinmux = <STM32_PINMUX('N', 11, AF14)>;
			};

			/omit-if-no-ref/ ltdc_b7_po2: ltdc_b7_po2 {
				pinmux = <STM32_PINMUX('O', 2, AF14)>;
			};

			/omit-if-no-ref/ ltdc_g3_po3: ltdc_g3_po3 {
				pinmux = <STM32_PINMUX('O', 3, AF14)>;
			};

			/omit-if-no-ref/ ltdc_b4_po4: ltdc_b4_po4 {
				pinmux = <STM32_PINMUX('O', 4, AF10)>;
			};

			/omit-if-no-ref/ ltdc_b5_pp15: ltdc_b5_pp15 {
				pinmux = <STM32_PINMUX('P', 15, AF14)>;
			};

			/* RCC_MCO */

			/omit-if-no-ref/ rcc_mco_1_pa8: rcc_mco_1_pa8 {
				pinmux = <STM32_PINMUX('A', 8, AF0)>;
				slew-rate = "very-high-speed";
			};

			/omit-if-no-ref/ rcc_mco_2_pc9: rcc_mco_2_pc9 {
				pinmux = <STM32_PINMUX('C', 9, AF0)>;
				slew-rate = "very-high-speed";
			};

			/* SDMMC */

			/omit-if-no-ref/ sdmmc1_cdir_pc1: sdmmc1_cdir_pc1 {
				pinmux = <STM32_PINMUX('C', 1, AF12)>;
				bias-pull-up;
				slew-rate = "very-high-speed";
			};

			/omit-if-no-ref/ sdmmc1_d5_pc1: sdmmc1_d5_pc1 {
				pinmux = <STM32_PINMUX('C', 1, AF10)>;
				bias-pull-up;
				slew-rate = "very-high-speed";
			};

			/omit-if-no-ref/ sdmmc1_d0dir_pc6: sdmmc1_d0dir_pc6 {
				pinmux = <STM32_PINMUX('C', 6, AF12)>;
				bias-pull-up;
				slew-rate = "very-high-speed";
			};

			/omit-if-no-ref/ sdmmc1_d6_pc6: sdmmc1_d6_pc6 {
				pinmux = <STM32_PINMUX('C', 6, AF10)>;
				bias-pull-up;
				slew-rate = "very-high-speed";
			};

			/omit-if-no-ref/ sdmmc1_d123dir_pc7: sdmmc1_d123dir_pc7 {
				pinmux = <STM32_PINMUX('C', 7, AF12)>;
				bias-pull-up;
				slew-rate = "very-high-speed";
			};

			/omit-if-no-ref/ sdmmc1_d7_pc7: sdmmc1_d7_pc7 {
				pinmux = <STM32_PINMUX('C', 7, AF10)>;
				bias-pull-up;
				slew-rate = "very-high-speed";
			};

			/omit-if-no-ref/ sdmmc1_d0_pc8: sdmmc1_d0_pc8 {
				pinmux = <STM32_PINMUX('C', 8, AF10)>;
				bias-pull-up;
				slew-rate = "very-high-speed";
			};

			/omit-if-no-ref/ sdmmc1_d1_pc9: sdmmc1_d1_pc9 {
				pinmux = <STM32_PINMUX('C', 9, AF10)>;
				bias-pull-up;
				slew-rate = "very-high-speed";
			};

			/omit-if-no-ref/ sdmmc1_d2_pc10: sdmmc1_d2_pc10 {
				pinmux = <STM32_PINMUX('C', 10, AF10)>;
				bias-pull-up;
				slew-rate = "very-high-speed";
			};

			/omit-if-no-ref/ sdmmc1_d3_pc11: sdmmc1_d3_pc11 {
				pinmux = <STM32_PINMUX('C', 11, AF10)>;
				bias-pull-up;
				slew-rate = "very-high-speed";
			};

			/omit-if-no-ref/ sdmmc1_ck_pc12: sdmmc1_ck_pc12 {
				pinmux = <STM32_PINMUX('C', 12, AF10)>;
				bias-pull-up;
				slew-rate = "very-high-speed";
			};

			/omit-if-no-ref/ sdmmc1_d0_pd11: sdmmc1_d0_pd11 {
				pinmux = <STM32_PINMUX('D', 11, AF10)>;
				bias-pull-up;
				slew-rate = "very-high-speed";
			};

			/omit-if-no-ref/ sdmmc1_cmd_ph2: sdmmc1_cmd_ph2 {
				pinmux = <STM32_PINMUX('H', 2, AF10)>;
				bias-pull-up;
				slew-rate = "very-high-speed";
			};

			/omit-if-no-ref/ sdmmc1_ckin_ph9: sdmmc1_ckin_ph9 {
				pinmux = <STM32_PINMUX('H', 9, AF12)>;
				bias-pull-up;
				slew-rate = "very-high-speed";
			};

			/omit-if-no-ref/ sdmmc1_d4_ph9: sdmmc1_d4_ph9 {
				pinmux = <STM32_PINMUX('H', 9, AF10)>;
				bias-pull-up;
				slew-rate = "very-high-speed";
			};

			/omit-if-no-ref/ sdmmc2_cmd_pa0: sdmmc2_cmd_pa0 {
				pinmux = <STM32_PINMUX('A', 0, AF11)>;
				bias-pull-up;
				slew-rate = "very-high-speed";
			};

			/omit-if-no-ref/ sdmmc2_d3_pb4: sdmmc2_d3_pb4 {
				pinmux = <STM32_PINMUX('B', 4, AF11)>;
				bias-pull-up;
				slew-rate = "very-high-speed";
			};

			/omit-if-no-ref/ sdmmc2_d0_pb8: sdmmc2_d0_pb8 {
				pinmux = <STM32_PINMUX('B', 8, AF11)>;
				bias-pull-up;
				slew-rate = "very-high-speed";
			};

			/omit-if-no-ref/ sdmmc2_d2_pc0: sdmmc2_d2_pc0 {
				pinmux = <STM32_PINMUX('C', 0, AF11)>;
				bias-pull-up;
				slew-rate = "very-high-speed";
			};

			/omit-if-no-ref/ sdmmc2_d5_pc1: sdmmc2_d5_pc1 {
				pinmux = <STM32_PINMUX('C', 1, AF11)>;
				bias-pull-up;
				slew-rate = "very-high-speed";
			};

			/omit-if-no-ref/ sdmmc2_ck_pc2: sdmmc2_ck_pc2 {
				pinmux = <STM32_PINMUX('C', 2, AF11)>;
				bias-pull-up;
				slew-rate = "very-high-speed";
			};

			/omit-if-no-ref/ sdmmc2_cmd_pc3: sdmmc2_cmd_pc3 {
				pinmux = <STM32_PINMUX('C', 3, AF11)>;
				bias-pull-up;
				slew-rate = "very-high-speed";
			};

			/omit-if-no-ref/ sdmmc2_d0_pc4: sdmmc2_d0_pc4 {
				pinmux = <STM32_PINMUX('C', 4, AF11)>;
				bias-pull-up;
				slew-rate = "very-high-speed";
			};

			/omit-if-no-ref/ sdmmc2_d1_pc5: sdmmc2_d1_pc5 {
				pinmux = <STM32_PINMUX('C', 5, AF11)>;
				bias-pull-up;
				slew-rate = "very-high-speed";
			};

			/omit-if-no-ref/ sdmmc2_d6_pc6: sdmmc2_d6_pc6 {
				pinmux = <STM32_PINMUX('C', 6, AF11)>;
				bias-pull-up;
				slew-rate = "very-high-speed";
			};

			/omit-if-no-ref/ sdmmc2_d7_pc7: sdmmc2_d7_pc7 {
				pinmux = <STM32_PINMUX('C', 7, AF11)>;
				bias-pull-up;
				slew-rate = "very-high-speed";
			};

			/omit-if-no-ref/ sdmmc2_d3_pe4: sdmmc2_d3_pe4 {
				pinmux = <STM32_PINMUX('E', 4, AF11)>;
				bias-pull-up;
				slew-rate = "very-high-speed";
			};

			/omit-if-no-ref/ sdmmc2_d4_ph9: sdmmc2_d4_ph9 {
				pinmux = <STM32_PINMUX('H', 9, AF11)>;
				bias-pull-up;
				slew-rate = "very-high-speed";
			};

			/* SPI_MISO */

			/omit-if-no-ref/ spi1_miso_pa6: spi1_miso_pa6 {
				pinmux = <STM32_PINMUX('A', 6, AF5)>;
				bias-pull-down;
				slew-rate = "very-high-speed";
			};

			/omit-if-no-ref/ spi1_miso_pb4: spi1_miso_pb4 {
				pinmux = <STM32_PINMUX('B', 4, AF5)>;
				bias-pull-down;
				slew-rate = "very-high-speed";
			};

			/omit-if-no-ref/ spi1_miso_pb8: spi1_miso_pb8 {
				pinmux = <STM32_PINMUX('B', 8, AF5)>;
				bias-pull-down;
				slew-rate = "very-high-speed";
			};

			/omit-if-no-ref/ spi2_miso_pc4: spi2_miso_pc4 {
				pinmux = <STM32_PINMUX('C', 4, AF5)>;
				bias-pull-down;
				slew-rate = "very-high-speed";
			};

			/omit-if-no-ref/ spi2_miso_pd11: spi2_miso_pd11 {
				pinmux = <STM32_PINMUX('D', 11, AF5)>;
				bias-pull-down;
				slew-rate = "very-high-speed";
			};

			/omit-if-no-ref/ spi2_miso_pp8: spi2_miso_pp8 {
				pinmux = <STM32_PINMUX('P', 8, AF5)>;
				bias-pull-down;
				slew-rate = "very-high-speed";
			};

			/omit-if-no-ref/ spi3_miso_pb4: spi3_miso_pb4 {
				pinmux = <STM32_PINMUX('B', 4, AF6)>;
				bias-pull-down;
				slew-rate = "very-high-speed";
			};

			/omit-if-no-ref/ spi3_miso_pc11: spi3_miso_pc11 {
				pinmux = <STM32_PINMUX('C', 11, AF6)>;
				bias-pull-down;
				slew-rate = "very-high-speed";
			};

			/omit-if-no-ref/ spi5_miso_pf12: spi5_miso_pf12 {
				pinmux = <STM32_PINMUX('F', 12, AF5)>;
				bias-pull-down;
				slew-rate = "very-high-speed";
			};

			/omit-if-no-ref/ spi6_miso_pa6: spi6_miso_pa6 {
				pinmux = <STM32_PINMUX('A', 6, AF8)>;
				bias-pull-down;
				slew-rate = "very-high-speed";
			};

			/omit-if-no-ref/ spi6_miso_pb4: spi6_miso_pb4 {
				pinmux = <STM32_PINMUX('B', 4, AF8)>;
				bias-pull-down;
				slew-rate = "very-high-speed";
			};

			/omit-if-no-ref/ spi6_miso_pe4: spi6_miso_pe4 {
				pinmux = <STM32_PINMUX('E', 4, AF5)>;
				bias-pull-down;
				slew-rate = "very-high-speed";
			};

			/* SPI_MOSI */

			/omit-if-no-ref/ spi1_mosi_pa7: spi1_mosi_pa7 {
				pinmux = <STM32_PINMUX('A', 7, AF5)>;
				bias-pull-down;
				slew-rate = "very-high-speed";
			};

			/omit-if-no-ref/ spi1_mosi_pb5: spi1_mosi_pb5 {
				pinmux = <STM32_PINMUX('B', 5, AF5)>;
				bias-pull-down;
				slew-rate = "very-high-speed";
			};

			/omit-if-no-ref/ spi1_mosi_pc3: spi1_mosi_pc3 {
				pinmux = <STM32_PINMUX('C', 3, AF5)>;
				bias-pull-down;
				slew-rate = "very-high-speed";
			};

			/omit-if-no-ref/ spi2_mosi_pp9: spi2_mosi_pp9 {
				pinmux = <STM32_PINMUX('P', 9, AF5)>;
				bias-pull-down;
				slew-rate = "very-high-speed";
			};

			/omit-if-no-ref/ spi3_mosi_pb5: spi3_mosi_pb5 {
				pinmux = <STM32_PINMUX('B', 5, AF7)>;
				bias-pull-down;
				slew-rate = "very-high-speed";
			};

			/omit-if-no-ref/ spi3_mosi_pc2: spi3_mosi_pc2 {
				pinmux = <STM32_PINMUX('C', 2, AF5)>;
				bias-pull-down;
				slew-rate = "very-high-speed";
			};

			/omit-if-no-ref/ spi3_mosi_pc12: spi3_mosi_pc12 {
				pinmux = <STM32_PINMUX('C', 12, AF6)>;
				bias-pull-down;
				slew-rate = "very-high-speed";
			};

			/omit-if-no-ref/ spi5_mosi_pf11: spi5_mosi_pf11 {
				pinmux = <STM32_PINMUX('F', 11, AF5)>;
				bias-pull-down;
				slew-rate = "very-high-speed";
			};

			/omit-if-no-ref/ spi5_mosi_pf14: spi5_mosi_pf14 {
				pinmux = <STM32_PINMUX('F', 14, AF5)>;
				bias-pull-down;
				slew-rate = "very-high-speed";
			};

			/omit-if-no-ref/ spi5_mosi_pg2: spi5_mosi_pg2 {
				pinmux = <STM32_PINMUX('G', 2, AF5)>;
				bias-pull-down;
				slew-rate = "very-high-speed";
			};

			/omit-if-no-ref/ spi6_mosi_pa7: spi6_mosi_pa7 {
				pinmux = <STM32_PINMUX('A', 7, AF8)>;
				bias-pull-down;
				slew-rate = "very-high-speed";
			};

			/omit-if-no-ref/ spi6_mosi_pb5: spi6_mosi_pb5 {
				pinmux = <STM32_PINMUX('B', 5, AF8)>;
				bias-pull-down;
				slew-rate = "very-high-speed";
			};

			/* SPI_NSS */

			/omit-if-no-ref/ spi1_nss_pa15: spi1_nss_pa15 {
				pinmux = <STM32_PINMUX('A', 15, AF5)>;
				bias-pull-up;
				slew-rate = "very-high-speed";
			};

			/omit-if-no-ref/ spi1_nss_pc5: spi1_nss_pc5 {
				pinmux = <STM32_PINMUX('C', 5, AF5)>;
				bias-pull-up;
				slew-rate = "very-high-speed";
			};

			/omit-if-no-ref/ spi1_nss_pf4: spi1_nss_pf4 {
				pinmux = <STM32_PINMUX('F', 4, AF5)>;
				bias-pull-up;
				slew-rate = "very-high-speed";
			};

			/omit-if-no-ref/ spi2_nss_pa11: spi2_nss_pa11 {
				pinmux = <STM32_PINMUX('A', 11, AF5)>;
				bias-pull-up;
				slew-rate = "very-high-speed";
			};

			/omit-if-no-ref/ spi2_nss_pb4: spi2_nss_pb4 {
				pinmux = <STM32_PINMUX('B', 4, AF7)>;
				bias-pull-up;
				slew-rate = "very-high-speed";
			};

			/omit-if-no-ref/ spi2_nss_pb12: spi2_nss_pb12 {
				pinmux = <STM32_PINMUX('B', 12, AF5)>;
				bias-pull-up;
				slew-rate = "very-high-speed";
			};

			/omit-if-no-ref/ spi2_nss_pc1: spi2_nss_pc1 {
				pinmux = <STM32_PINMUX('C', 1, AF5)>;
				bias-pull-up;
				slew-rate = "very-high-speed";
			};

			/omit-if-no-ref/ spi3_nss_pa15: spi3_nss_pa15 {
				pinmux = <STM32_PINMUX('A', 15, AF6)>;
				bias-pull-up;
				slew-rate = "very-high-speed";
			};

			/omit-if-no-ref/ spi3_nss_pf4: spi3_nss_pf4 {
				pinmux = <STM32_PINMUX('F', 4, AF6)>;
				bias-pull-up;
				slew-rate = "very-high-speed";
			};

			/omit-if-no-ref/ spi5_nss_pf13: spi5_nss_pf13 {
				pinmux = <STM32_PINMUX('F', 13, AF5)>;
				bias-pull-up;
				slew-rate = "very-high-speed";
			};

			/omit-if-no-ref/ spi6_nss_pa0: spi6_nss_pa0 {
				pinmux = <STM32_PINMUX('A', 0, AF5)>;
				bias-pull-up;
				slew-rate = "very-high-speed";
			};

			/omit-if-no-ref/ spi6_nss_pa15: spi6_nss_pa15 {
				pinmux = <STM32_PINMUX('A', 15, AF7)>;
				bias-pull-up;
				slew-rate = "very-high-speed";
			};

			/omit-if-no-ref/ spi6_nss_pf4: spi6_nss_pf4 {
				pinmux = <STM32_PINMUX('F', 4, AF8)>;
				bias-pull-up;
				slew-rate = "very-high-speed";
			};

			/* SPI_SCK */

			/omit-if-no-ref/ spi1_sck_pa5: spi1_sck_pa5 {
				pinmux = <STM32_PINMUX('A', 5, AF5)>;
				bias-pull-down;
				slew-rate = "very-high-speed";
			};

			/omit-if-no-ref/ spi1_sck_pc0: spi1_sck_pc0 {
				pinmux = <STM32_PINMUX('C', 0, AF5)>;
				bias-pull-down;
				slew-rate = "very-high-speed";
			};

			/omit-if-no-ref/ spi1_sck_pf7: spi1_sck_pf7 {
				pinmux = <STM32_PINMUX('F', 7, AF5)>;
				bias-pull-down;
				slew-rate = "very-high-speed";
			};

			/omit-if-no-ref/ spi2_sck_pa9: spi2_sck_pa9 {
				pinmux = <STM32_PINMUX('A', 9, AF5)>;
				bias-pull-down;
				slew-rate = "very-high-speed";
			};

			/omit-if-no-ref/ spi2_sck_pa12: spi2_sck_pa12 {
				pinmux = <STM32_PINMUX('A', 12, AF5)>;
				bias-pull-down;
				slew-rate = "very-high-speed";
			};

			/omit-if-no-ref/ spi2_sck_pb10: spi2_sck_pb10 {
				pinmux = <STM32_PINMUX('B', 10, AF5)>;
				bias-pull-down;
				slew-rate = "very-high-speed";
			};

			/omit-if-no-ref/ spi2_sck_pf2: spi2_sck_pf2 {
				pinmux = <STM32_PINMUX('F', 2, AF5)>;
				bias-pull-down;
				slew-rate = "very-high-speed";
			};

			/omit-if-no-ref/ spi2_sck_pg10: spi2_sck_pg10 {
				pinmux = <STM32_PINMUX('G', 10, AF5)>;
				bias-pull-down;
				slew-rate = "very-high-speed";
			};

			/omit-if-no-ref/ spi3_sck_pc0: spi3_sck_pc0 {
				pinmux = <STM32_PINMUX('C', 0, AF6)>;
				bias-pull-down;
				slew-rate = "very-high-speed";
			};

			/omit-if-no-ref/ spi3_sck_pc10: spi3_sck_pc10 {
				pinmux = <STM32_PINMUX('C', 10, AF6)>;
				bias-pull-down;
				slew-rate = "very-high-speed";
			};

			/omit-if-no-ref/ spi5_sck_pf15: spi5_sck_pf15 {
				pinmux = <STM32_PINMUX('F', 15, AF5)>;
				bias-pull-down;
				slew-rate = "very-high-speed";
			};

			/omit-if-no-ref/ spi6_sck_pa5: spi6_sck_pa5 {
				pinmux = <STM32_PINMUX('A', 5, AF8)>;
				bias-pull-down;
				slew-rate = "very-high-speed";
			};

			/omit-if-no-ref/ spi6_sck_pc0: spi6_sck_pc0 {
				pinmux = <STM32_PINMUX('C', 0, AF8)>;
				bias-pull-down;
				slew-rate = "very-high-speed";
			};

			/omit-if-no-ref/ spi6_sck_pc12: spi6_sck_pc12 {
				pinmux = <STM32_PINMUX('C', 12, AF5)>;
				bias-pull-down;
				slew-rate = "very-high-speed";
			};

			/* TIM_BKIN */

			/omit-if-no-ref/ tim15_bkin_pa0: tim15_bkin_pa0 {
				pinmux = <STM32_PINMUX('A', 0, AF4)>;
			};

			/omit-if-no-ref/ tim15_bkin_pe3: tim15_bkin_pe3 {
				pinmux = <STM32_PINMUX('E', 3, AF7)>;
			};

			/omit-if-no-ref/ tim15_bkin_ph2: tim15_bkin_ph2 {
				pinmux = <STM32_PINMUX('H', 2, AF4)>;
			};

			/omit-if-no-ref/ tim16_bkin_pb4: tim16_bkin_pb4 {
				pinmux = <STM32_PINMUX('B', 4, AF1)>;
			};

			/omit-if-no-ref/ tim16_bkin_pf10: tim16_bkin_pf10 {
				pinmux = <STM32_PINMUX('F', 10, AF1)>;
			};

			/omit-if-no-ref/ tim17_bkin_pb5: tim17_bkin_pb5 {
				pinmux = <STM32_PINMUX('B', 5, AF1)>;
			};

			/* TIM_CH / TIM_CHN */

			/omit-if-no-ref/ tim10_ch1_pa5: tim10_ch1_pa5 {
				pinmux = <STM32_PINMUX('A', 5, AF10)>;
			};

			/omit-if-no-ref/ tim11_ch1_pa8: tim11_ch1_pa8 {
				pinmux = <STM32_PINMUX('A', 8, AF9)>;
			};

			/omit-if-no-ref/ tim2_ch1_pa0: tim2_ch1_pa0 {
				pinmux = <STM32_PINMUX('A', 0, AF1)>;
			};

			/omit-if-no-ref/ tim2_ch2_pa1: tim2_ch2_pa1 {
				pinmux = <STM32_PINMUX('A', 1, AF1)>;
			};

			/omit-if-no-ref/ tim2_ch3_pa2: tim2_ch3_pa2 {
				pinmux = <STM32_PINMUX('A', 2, AF1)>;
			};

			/omit-if-no-ref/ tim2_ch1_pa5: tim2_ch1_pa5 {
				pinmux = <STM32_PINMUX('A', 5, AF1)>;
			};

			/omit-if-no-ref/ tim2_ch1_pa15: tim2_ch1_pa15 {
				pinmux = <STM32_PINMUX('A', 15, AF1)>;
			};

			/omit-if-no-ref/ tim2_ch3_pb10: tim2_ch3_pb10 {
				pinmux = <STM32_PINMUX('B', 10, AF1)>;
			};

			/omit-if-no-ref/ tim2_ch4_pb11: tim2_ch4_pb11 {
				pinmux = <STM32_PINMUX('B', 11, AF1)>;
			};

			/omit-if-no-ref/ tim2_ch2_pc0: tim2_ch2_pc0 {
				pinmux = <STM32_PINMUX('C', 0, AF1)>;
			};

			/omit-if-no-ref/ tim2_ch2_pf14: tim2_ch2_pf14 {
				pinmux = <STM32_PINMUX('F', 14, AF1)>;
			};

			/omit-if-no-ref/ tim13_ch1_pa6: tim13_ch1_pa6 {
				pinmux = <STM32_PINMUX('A', 6, AF10)>;
			};

			/omit-if-no-ref/ tim3_ch1_pa6: tim3_ch1_pa6 {
				pinmux = <STM32_PINMUX('A', 6, AF2)>;
			};

			/omit-if-no-ref/ tim3_ch2_pa7: tim3_ch2_pa7 {
				pinmux = <STM32_PINMUX('A', 7, AF2)>;
			};

			/omit-if-no-ref/ tim3_ch1_pb4: tim3_ch1_pb4 {
				pinmux = <STM32_PINMUX('B', 4, AF2)>;
			};

			/omit-if-no-ref/ tim3_ch2_pb5: tim3_ch2_pb5 {
				pinmux = <STM32_PINMUX('B', 5, AF2)>;
			};

			/omit-if-no-ref/ tim3_ch1_pc6: tim3_ch1_pc6 {
				pinmux = <STM32_PINMUX('C', 6, AF2)>;
			};

			/omit-if-no-ref/ tim3_ch2_pc7: tim3_ch2_pc7 {
				pinmux = <STM32_PINMUX('C', 7, AF2)>;
			};

			/omit-if-no-ref/ tim3_ch3_pc8: tim3_ch3_pc8 {
				pinmux = <STM32_PINMUX('C', 8, AF2)>;
			};

			/omit-if-no-ref/ tim3_ch4_pc9: tim3_ch4_pc9 {
				pinmux = <STM32_PINMUX('C', 9, AF2)>;
			};

			/omit-if-no-ref/ tim3_ch3_pf7: tim3_ch3_pf7 {
				pinmux = <STM32_PINMUX('F', 7, AF2)>;
			};

			/omit-if-no-ref/ tim14_ch1_pa7: tim14_ch1_pa7 {
				pinmux = <STM32_PINMUX('A', 7, AF11)>;
			};

			/omit-if-no-ref/ tim4_ch4_pc1: tim4_ch4_pc1 {
				pinmux = <STM32_PINMUX('C', 1, AF2)>;
			};

			/omit-if-no-ref/ tim4_ch1_pe5: tim4_ch1_pe5 {
				pinmux = <STM32_PINMUX('E', 5, AF2)>;
			};

			/omit-if-no-ref/ tim4_ch2_pe6: tim4_ch2_pe6 {
				pinmux = <STM32_PINMUX('E', 6, AF2)>;
			};

			/omit-if-no-ref/ tim14_ch1_pg2: tim14_ch1_pg2 {
				pinmux = <STM32_PINMUX('G', 2, AF11)>;
			};

			/omit-if-no-ref/ tim4_ch1_pg13: tim4_ch1_pg13 {
				pinmux = <STM32_PINMUX('G', 13, AF2)>;
			};

			/omit-if-no-ref/ tim4_ch3_ph9: tim4_ch3_ph9 {
				pinmux = <STM32_PINMUX('H', 9, AF2)>;
			};

			/omit-if-no-ref/ tim15_ch1n_pa1: tim15_ch1n_pa1 {
				pinmux = <STM32_PINMUX('A', 1, AF4)>;
			};

			/omit-if-no-ref/ tim15_ch1_pa2: tim15_ch1_pa2 {
				pinmux = <STM32_PINMUX('A', 2, AF4)>;
			};

			/omit-if-no-ref/ tim15_ch1_pb6: tim15_ch1_pb6 {
				pinmux = <STM32_PINMUX('B', 6, AF7)>;
			};

			/omit-if-no-ref/ tim15_ch2_pb7: tim15_ch2_pb7 {
				pinmux = <STM32_PINMUX('B', 7, AF7)>;
			};

			/omit-if-no-ref/ tim15_ch1_pc12: tim15_ch1_pc12 {
				pinmux = <STM32_PINMUX('C', 12, AF4)>;
			};

			/omit-if-no-ref/ tim16_ch1n_pc7: tim16_ch1n_pc7 {
				pinmux = <STM32_PINMUX('C', 7, AF1)>;
			};

			/omit-if-no-ref/ tim16_ch1n_pe5: tim16_ch1n_pe5 {
				pinmux = <STM32_PINMUX('E', 5, AF1)>;
			};

			/omit-if-no-ref/ tim16_ch1_ph9: tim16_ch1_ph9 {
				pinmux = <STM32_PINMUX('H', 9, AF1)>;
			};

			/omit-if-no-ref/ tim17_ch1_pc1: tim17_ch1_pc1 {
				pinmux = <STM32_PINMUX('C', 1, AF1)>;
			};

			/omit-if-no-ref/ tim17_ch1n_pe6: tim17_ch1n_pe6 {
				pinmux = <STM32_PINMUX('E', 6, AF1)>;
			};

			/omit-if-no-ref/ tim17_ch1n_pg2: tim17_ch1n_pg2 {
				pinmux = <STM32_PINMUX('G', 2, AF1)>;
			};

			/omit-if-no-ref/ tim9_ch1_pa0: tim9_ch1_pa0 {
				pinmux = <STM32_PINMUX('A', 0, AF3)>;
			};

			/omit-if-no-ref/ tim9_ch2_pa5: tim9_ch2_pa5 {
				pinmux = <STM32_PINMUX('A', 5, AF3)>;
			};

			/omit-if-no-ref/ tim9_ch1_pc6: tim9_ch1_pc6 {
				pinmux = <STM32_PINMUX('C', 6, AF3)>;
			};

			/omit-if-no-ref/ tim9_ch2_pc7: tim9_ch2_pc7 {
				pinmux = <STM32_PINMUX('C', 7, AF3)>;
			};

			/omit-if-no-ref/ tim9_ch1_pf7: tim9_ch1_pf7 {
				pinmux = <STM32_PINMUX('F', 7, AF3)>;
			};

			/* UART_CTS / USART_CTS / LPUART_CTS */

			/omit-if-no-ref/ lpuart1_cts_pa11: lpuart1_cts_pa11 {
				pinmux = <STM32_PINMUX('A', 11, AF3)>;
				bias-pull-up;
			};

			/omit-if-no-ref/ usart1_cts_pa11: usart1_cts_pa11 {
				pinmux = <STM32_PINMUX('A', 11, AF7)>;
				bias-pull-up;
			};

			/omit-if-no-ref/ usart1_cts_pf14: usart1_cts_pf14 {
				pinmux = <STM32_PINMUX('F', 14, AF4)>;
				bias-pull-up;
			};

			/omit-if-no-ref/ usart2_cts_pa0: usart2_cts_pa0 {
				pinmux = <STM32_PINMUX('A', 0, AF7)>;
				bias-pull-up;
			};

			/omit-if-no-ref/ usart2_cts_pf2: usart2_cts_pf2 {
				pinmux = <STM32_PINMUX('F', 2, AF7)>;
				bias-pull-up;
			};

			/omit-if-no-ref/ usart3_cts_pf5: usart3_cts_pf5 {
				pinmux = <STM32_PINMUX('F', 5, AF7)>;
				bias-pull-up;
			};

			/omit-if-no-ref/ usart3_cts_pg10: usart3_cts_pg10 {
				pinmux = <STM32_PINMUX('G', 10, AF7)>;
				bias-pull-up;
			};

			/omit-if-no-ref/ uart4_cts_pf7: uart4_cts_pf7 {
				pinmux = <STM32_PINMUX('F', 7, AF8)>;
				bias-pull-up;
			};

			/omit-if-no-ref/ uart5_cts_pc9: uart5_cts_pc9 {
				pinmux = <STM32_PINMUX('C', 9, AF11)>;
				bias-pull-up;
			};

			/omit-if-no-ref/ uart7_cts_pe10: uart7_cts_pe10 {
				pinmux = <STM32_PINMUX('E', 10, AF8)>;
				bias-pull-up;
			};

			/omit-if-no-ref/ uart7_cts_pg2: uart7_cts_pg2 {
				pinmux = <STM32_PINMUX('G', 2, AF8)>;
				bias-pull-up;
			};

			/* UART_DE / USART_DE / LPUART_DE */

			/omit-if-no-ref/ lpuart1_de_pa12: lpuart1_de_pa12 {
				pinmux = <STM32_PINMUX('A', 12, AF3)>;
				drive-push-pull;
			};

			/omit-if-no-ref/ usart1_de_pa12: usart1_de_pa12 {
				pinmux = <STM32_PINMUX('A', 12, AF7)>;
				drive-push-pull;
			};

			/omit-if-no-ref/ usart1_de_pf15: usart1_de_pf15 {
				pinmux = <STM32_PINMUX('F', 15, AF4)>;
				drive-push-pull;
			};

			/omit-if-no-ref/ usart2_de_pa1: usart2_de_pa1 {
				pinmux = <STM32_PINMUX('A', 1, AF7)>;
				drive-push-pull;
			};

			/omit-if-no-ref/ usart3_de_pc4: usart3_de_pc4 {
				pinmux = <STM32_PINMUX('C', 4, AF7)>;
				drive-push-pull;
			};

			/omit-if-no-ref/ usart3_de_pg2: usart3_de_pg2 {
				pinmux = <STM32_PINMUX('G', 2, AF7)>;
				drive-push-pull;
			};

			/omit-if-no-ref/ usart3_de_pg13: usart3_de_pg13 {
				pinmux = <STM32_PINMUX('G', 13, AF7)>;
				drive-push-pull;
			};

			/omit-if-no-ref/ uart4_de_pa15: uart4_de_pa15 {
				pinmux = <STM32_PINMUX('A', 15, AF8)>;
				drive-push-pull;
			};

			/omit-if-no-ref/ uart4_de_pc4: uart4_de_pc4 {
				pinmux = <STM32_PINMUX('C', 4, AF8)>;
				drive-push-pull;
			};

			/omit-if-no-ref/ uart5_de_pc8: uart5_de_pc8 {
				pinmux = <STM32_PINMUX('C', 8, AF11)>;
				drive-push-pull;
			};

			/omit-if-no-ref/ uart7_de_pe9: uart7_de_pe9 {
				pinmux = <STM32_PINMUX('E', 9, AF8)>;
				drive-push-pull;
			};

			/* UART_RTS / USART_RTS / LPUART_RTS */

			/omit-if-no-ref/ lpuart1_rts_pa12: lpuart1_rts_pa12 {
				pinmux = <STM32_PINMUX('A', 12, AF3)>;
				drive-push-pull;
			};

			/omit-if-no-ref/ usart1_rts_pa12: usart1_rts_pa12 {
				pinmux = <STM32_PINMUX('A', 12, AF7)>;
				drive-push-pull;
			};

			/omit-if-no-ref/ usart1_rts_pf15: usart1_rts_pf15 {
				pinmux = <STM32_PINMUX('F', 15, AF4)>;
				drive-push-pull;
			};

			/omit-if-no-ref/ usart2_rts_pa1: usart2_rts_pa1 {
				pinmux = <STM32_PINMUX('A', 1, AF7)>;
				drive-push-pull;
			};

			/omit-if-no-ref/ usart3_rts_pc4: usart3_rts_pc4 {
				pinmux = <STM32_PINMUX('C', 4, AF7)>;
				drive-push-pull;
			};

			/omit-if-no-ref/ usart3_rts_pg2: usart3_rts_pg2 {
				pinmux = <STM32_PINMUX('G', 2, AF7)>;
				drive-push-pull;
			};

			/omit-if-no-ref/ usart3_rts_pg13: usart3_rts_pg13 {
				pinmux = <STM32_PINMUX('G', 13, AF7)>;
				drive-push-pull;
			};

			/omit-if-no-ref/ uart4_rts_pa15: uart4_rts_pa15 {
				pinmux = <STM32_PINMUX('A', 15, AF8)>;
				drive-push-pull;
			};

			/omit-if-no-ref/ uart4_rts_pc4: uart4_rts_pc4 {
				pinmux = <STM32_PINMUX('C', 4, AF8)>;
				drive-push-pull;
			};

			/omit-if-no-ref/ uart5_rts_pc8: uart5_rts_pc8 {
				pinmux = <STM32_PINMUX('C', 8, AF11)>;
				drive-push-pull;
			};

			/omit-if-no-ref/ uart7_rts_pe9: uart7_rts_pe9 {
				pinmux = <STM32_PINMUX('E', 9, AF8)>;
				drive-push-pull;
			};

			/* UART_RX / USART_RX / LPUART_RX */

			/omit-if-no-ref/ usart1_rx_pa7: usart1_rx_pa7 {
				pinmux = <STM32_PINMUX('A', 7, AF7)>;
			};

			/omit-if-no-ref/ lpuart1_rx_pa10: lpuart1_rx_pa10 {
				pinmux = <STM32_PINMUX('A', 10, AF3)>;
			};

			/omit-if-no-ref/ usart1_rx_pa10: usart1_rx_pa10 {
				pinmux = <STM32_PINMUX('A', 10, AF7)>;
			};

			/omit-if-no-ref/ lpuart1_rx_pe6: lpuart1_rx_pe6 {
				pinmux = <STM32_PINMUX('E', 6, AF3)>;
			};

			/omit-if-no-ref/ usart1_rx_pe6: usart1_rx_pe6 {
				pinmux = <STM32_PINMUX('E', 6, AF7)>;
			};

			/omit-if-no-ref/ usart1_rx_pf12: usart1_rx_pf12 {
				pinmux = <STM32_PINMUX('F', 12, AF4)>;
			};

			/omit-if-no-ref/ usart2_rx_pc2: usart2_rx_pc2 {
				pinmux = <STM32_PINMUX('C', 2, AF7)>;
			};

			/omit-if-no-ref/ usart3_rx_pb11: usart3_rx_pb11 {
				pinmux = <STM32_PINMUX('B', 11, AF7)>;
			};

			/omit-if-no-ref/ usart3_rx_pc11: usart3_rx_pc11 {
				pinmux = <STM32_PINMUX('C', 11, AF7)>;
			};

			/omit-if-no-ref/ usart3_rx_pe0: usart3_rx_pe0 {
				pinmux = <STM32_PINMUX('E', 0, AF7)>;
			};

			/omit-if-no-ref/ usart3_rx_pe10: usart3_rx_pe10 {
				pinmux = <STM32_PINMUX('E', 10, AF7)>;
			};

			/omit-if-no-ref/ uart4_rx_pa1: uart4_rx_pa1 {
				pinmux = <STM32_PINMUX('A', 1, AF8)>;
			};

			/omit-if-no-ref/ uart4_rx_pa11: uart4_rx_pa11 {
				pinmux = <STM32_PINMUX('A', 11, AF8)>;
			};

			/omit-if-no-ref/ uart4_rx_pc11: uart4_rx_pc11 {
				pinmux = <STM32_PINMUX('C', 11, AF8)>;
			};

			/omit-if-no-ref/ uart4_rx_ph9: uart4_rx_ph9 {
				pinmux = <STM32_PINMUX('H', 9, AF8)>;
			};

			/omit-if-no-ref/ uart5_rx_pb5: uart5_rx_pb5 {
				pinmux = <STM32_PINMUX('B', 5, AF11)>;
			};

			/omit-if-no-ref/ uart5_rx_pb12: uart5_rx_pb12 {
				pinmux = <STM32_PINMUX('B', 12, AF11)>;
			};

			/omit-if-no-ref/ uart5_rx_ph2: uart5_rx_ph2 {
				pinmux = <STM32_PINMUX('H', 2, AF11)>;
			};

			/omit-if-no-ref/ uart7_rx_pa8: uart7_rx_pa8 {
				pinmux = <STM32_PINMUX('A', 8, AF10)>;
			};

			/omit-if-no-ref/ uart7_rx_pc0: uart7_rx_pc0 {
				pinmux = <STM32_PINMUX('C', 0, AF10)>;
			};

			/omit-if-no-ref/ uart7_rx_pe7: uart7_rx_pe7 {
				pinmux = <STM32_PINMUX('E', 7, AF8)>;
			};

			/omit-if-no-ref/ uart7_rx_pf10: uart7_rx_pf10 {
				pinmux = <STM32_PINMUX('F', 10, AF8)>;
			};

			/* UART_TX / USART_TX / LPUART_TX */

			/omit-if-no-ref/ lpuart1_tx_pa9: lpuart1_tx_pa9 {
				pinmux = <STM32_PINMUX('A', 9, AF3)>;
				bias-pull-up;
			};

			/omit-if-no-ref/ usart1_tx_pa9: usart1_tx_pa9 {
				pinmux = <STM32_PINMUX('A', 9, AF7)>;
				bias-pull-up;
			};

			/omit-if-no-ref/ usart1_tx_pc4: usart1_tx_pc4 {
				pinmux = <STM32_PINMUX('C', 4, AF4)>;
				bias-pull-up;
			};

			/omit-if-no-ref/ lpuart1_tx_pe5: lpuart1_tx_pe5 {
				pinmux = <STM32_PINMUX('E', 5, AF3)>;
				bias-pull-up;
			};

			/omit-if-no-ref/ usart1_tx_pe5: usart1_tx_pe5 {
				pinmux = <STM32_PINMUX('E', 5, AF7)>;
				bias-pull-up;
			};

			/omit-if-no-ref/ usart1_tx_pf13: usart1_tx_pf13 {
				pinmux = <STM32_PINMUX('F', 13, AF4)>;
				bias-pull-up;
			};

			/omit-if-no-ref/ usart2_tx_pa2: usart2_tx_pa2 {
				pinmux = <STM32_PINMUX('A', 2, AF7)>;
				bias-pull-up;
			};

			/omit-if-no-ref/ usart3_tx_pb10: usart3_tx_pb10 {
				pinmux = <STM32_PINMUX('B', 10, AF7)>;
				bias-pull-up;
			};

			/omit-if-no-ref/ usart3_tx_pc10: usart3_tx_pc10 {
				pinmux = <STM32_PINMUX('C', 10, AF7)>;
				bias-pull-up;
			};

			/omit-if-no-ref/ usart3_tx_pd8: usart3_tx_pd8 {
				pinmux = <STM32_PINMUX('D', 8, AF7)>;
				bias-pull-up;
			};

			/omit-if-no-ref/ usart3_tx_pe1: usart3_tx_pe1 {
				pinmux = <STM32_PINMUX('E', 1, AF7)>;
				bias-pull-up;
			};

			/omit-if-no-ref/ usart3_tx_pe8: usart3_tx_pe8 {
				pinmux = <STM32_PINMUX('E', 8, AF7)>;
				bias-pull-up;
			};

			/omit-if-no-ref/ uart4_tx_pa0: uart4_tx_pa0 {
				pinmux = <STM32_PINMUX('A', 0, AF8)>;
				bias-pull-up;
			};

			/omit-if-no-ref/ uart4_tx_pa12: uart4_tx_pa12 {
				pinmux = <STM32_PINMUX('A', 12, AF8)>;
				bias-pull-up;
			};

			/omit-if-no-ref/ uart4_tx_pc1: uart4_tx_pc1 {
				pinmux = <STM32_PINMUX('C', 1, AF8)>;
				bias-pull-up;
			};

			/omit-if-no-ref/ uart4_tx_pc10: uart4_tx_pc10 {
				pinmux = <STM32_PINMUX('C', 10, AF8)>;
				bias-pull-up;
			};

			/omit-if-no-ref/ uart5_tx_pc12: uart5_tx_pc12 {
				pinmux = <STM32_PINMUX('C', 12, AF11)>;
				bias-pull-up;
			};

			/omit-if-no-ref/ uart5_tx_pe5: uart5_tx_pe5 {
				pinmux = <STM32_PINMUX('E', 5, AF11)>;
				bias-pull-up;
			};

			/omit-if-no-ref/ uart5_tx_pe6: uart5_tx_pe6 {
				pinmux = <STM32_PINMUX('E', 6, AF11)>;
				bias-pull-up;
			};

			/omit-if-no-ref/ uart5_tx_pg10: uart5_tx_pg10 {
				pinmux = <STM32_PINMUX('G', 10, AF11)>;
				bias-pull-up;
			};

			/omit-if-no-ref/ uart7_tx_pa15: uart7_tx_pa15 {
				pinmux = <STM32_PINMUX('A', 15, AF10)>;
				bias-pull-up;
			};

			/omit-if-no-ref/ uart7_tx_pb4: uart7_tx_pb4 {
				pinmux = <STM32_PINMUX('B', 4, AF10)>;
				bias-pull-up;
			};

			/omit-if-no-ref/ uart7_tx_pe8: uart7_tx_pe8 {
				pinmux = <STM32_PINMUX('E', 8, AF8)>;
				bias-pull-up;
			};

			/* XSPIM */

			/omit-if-no-ref/ xspim_p2_dqs0_pn0: xspim_p2_dqs0_pn0 {
				pinmux = <STM32_PINMUX('N', 0, AF9)>;
				slew-rate = "very-high-speed";
			};

			/omit-if-no-ref/ xspim_p2_ncs1_pn1: xspim_p2_ncs1_pn1 {
				pinmux = <STM32_PINMUX('N', 1, AF9)>;
				slew-rate = "very-high-speed";
			};

			/omit-if-no-ref/ xspim_p2_io0_pn2: xspim_p2_io0_pn2 {
				pinmux = <STM32_PINMUX('N', 2, AF9)>;
				slew-rate = "very-high-speed";
			};

			/omit-if-no-ref/ xspim_p2_io1_pn3: xspim_p2_io1_pn3 {
				pinmux = <STM32_PINMUX('N', 3, AF9)>;
				slew-rate = "very-high-speed";
			};

			/omit-if-no-ref/ xspim_p2_io2_pn4: xspim_p2_io2_pn4 {
				pinmux = <STM32_PINMUX('N', 4, AF9)>;
				slew-rate = "very-high-speed";
			};

			/omit-if-no-ref/ xspim_p2_io3_pn5: xspim_p2_io3_pn5 {
				pinmux = <STM32_PINMUX('N', 5, AF9)>;
				slew-rate = "very-high-speed";
			};

			/omit-if-no-ref/ xspim_p2_clk_pn6: xspim_p2_clk_pn6 {
				pinmux = <STM32_PINMUX('N', 6, AF9)>;
				slew-rate = "very-high-speed";
			};

			/omit-if-no-ref/ xspim_p2_nclk_pn7: xspim_p2_nclk_pn7 {
				pinmux = <STM32_PINMUX('N', 7, AF9)>;
				slew-rate = "very-high-speed";
			};

			/omit-if-no-ref/ xspim_p2_io4_pn8: xspim_p2_io4_pn8 {
				pinmux = <STM32_PINMUX('N', 8, AF9)>;
				slew-rate = "very-high-speed";
			};

			/omit-if-no-ref/ xspim_p2_io5_pn9: xspim_p2_io5_pn9 {
				pinmux = <STM32_PINMUX('N', 9, AF9)>;
				slew-rate = "very-high-speed";
			};

			/omit-if-no-ref/ xspim_p2_io6_pn10: xspim_p2_io6_pn10 {
				pinmux = <STM32_PINMUX('N', 10, AF9)>;
				slew-rate = "very-high-speed";
			};

			/omit-if-no-ref/ xspim_p2_io7_pn11: xspim_p2_io7_pn11 {
				pinmux = <STM32_PINMUX('N', 11, AF9)>;
				slew-rate = "very-high-speed";
			};

			/omit-if-no-ref/ xspim_p2_ncs2_pn12: xspim_p2_ncs2_pn12 {
				pinmux = <STM32_PINMUX('N', 12, AF9)>;
				slew-rate = "very-high-speed";
			};

			/omit-if-no-ref/ xspim_p1_ncs1_po0: xspim_p1_ncs1_po0 {
				pinmux = <STM32_PINMUX('O', 0, AF9)>;
				slew-rate = "very-high-speed";
			};

			/omit-if-no-ref/ xspim_p1_ncs2_po1: xspim_p1_ncs2_po1 {
				pinmux = <STM32_PINMUX('O', 1, AF9)>;
				slew-rate = "very-high-speed";
			};

			/omit-if-no-ref/ xspim_p1_dqs0_po2: xspim_p1_dqs0_po2 {
				pinmux = <STM32_PINMUX('O', 2, AF9)>;
				slew-rate = "very-high-speed";
			};

			/omit-if-no-ref/ xspim_p1_dqs1_po3: xspim_p1_dqs1_po3 {
				pinmux = <STM32_PINMUX('O', 3, AF9)>;
				slew-rate = "very-high-speed";
			};

			/omit-if-no-ref/ xspim_p1_clk_po4: xspim_p1_clk_po4 {
				pinmux = <STM32_PINMUX('O', 4, AF9)>;
				slew-rate = "very-high-speed";
			};

			/omit-if-no-ref/ xspim_p1_nclk_po5: xspim_p1_nclk_po5 {
				pinmux = <STM32_PINMUX('O', 5, AF9)>;
				slew-rate = "very-high-speed";
			};

			/omit-if-no-ref/ xspim_p1_io0_pp0: xspim_p1_io0_pp0 {
				pinmux = <STM32_PINMUX('P', 0, AF9)>;
				slew-rate = "very-high-speed";
			};

			/omit-if-no-ref/ xspim_p1_io1_pp1: xspim_p1_io1_pp1 {
				pinmux = <STM32_PINMUX('P', 1, AF9)>;
				slew-rate = "very-high-speed";
			};

			/omit-if-no-ref/ xspim_p1_io2_pp2: xspim_p1_io2_pp2 {
				pinmux = <STM32_PINMUX('P', 2, AF9)>;
				slew-rate = "very-high-speed";
			};

			/omit-if-no-ref/ xspim_p1_io3_pp3: xspim_p1_io3_pp3 {
				pinmux = <STM32_PINMUX('P', 3, AF9)>;
				slew-rate = "very-high-speed";
			};

			/omit-if-no-ref/ xspim_p1_io4_pp4: xspim_p1_io4_pp4 {
				pinmux = <STM32_PINMUX('P', 4, AF9)>;
				slew-rate = "very-high-speed";
			};

			/omit-if-no-ref/ xspim_p1_io5_pp5: xspim_p1_io5_pp5 {
				pinmux = <STM32_PINMUX('P', 5, AF9)>;
				slew-rate = "very-high-speed";
			};

			/omit-if-no-ref/ xspim_p1_io6_pp6: xspim_p1_io6_pp6 {
				pinmux = <STM32_PINMUX('P', 6, AF9)>;
				slew-rate = "very-high-speed";
			};

			/omit-if-no-ref/ xspim_p1_io7_pp7: xspim_p1_io7_pp7 {
				pinmux = <STM32_PINMUX('P', 7, AF9)>;
				slew-rate = "very-high-speed";
			};

			/omit-if-no-ref/ xspim_p1_io8_pp8: xspim_p1_io8_pp8 {
				pinmux = <STM32_PINMUX('P', 8, AF9)>;
				slew-rate = "very-high-speed";
			};

			/omit-if-no-ref/ xspim_p1_io9_pp9: xspim_p1_io9_pp9 {
				pinmux = <STM32_PINMUX('P', 9, AF9)>;
				slew-rate = "very-high-speed";
			};

			/omit-if-no-ref/ xspim_p1_io10_pp10: xspim_p1_io10_pp10 {
				pinmux = <STM32_PINMUX('P', 10, AF9)>;
				slew-rate = "very-high-speed";
			};

			/omit-if-no-ref/ xspim_p1_io11_pp11: xspim_p1_io11_pp11 {
				pinmux = <STM32_PINMUX('P', 11, AF9)>;
				slew-rate = "very-high-speed";
			};

			/omit-if-no-ref/ xspim_p1_io12_pp12: xspim_p1_io12_pp12 {
				pinmux = <STM32_PINMUX('P', 12, AF9)>;
				slew-rate = "very-high-speed";
			};

			/omit-if-no-ref/ xspim_p1_io13_pp13: xspim_p1_io13_pp13 {
				pinmux = <STM32_PINMUX('P', 13, AF9)>;
				slew-rate = "very-high-speed";
			};

			/omit-if-no-ref/ xspim_p1_io14_pp14: xspim_p1_io14_pp14 {
				pinmux = <STM32_PINMUX('P', 14, AF9)>;
				slew-rate = "very-high-speed";
			};

			/omit-if-no-ref/ xspim_p1_io15_pp15: xspim_p1_io15_pp15 {
				pinmux = <STM32_PINMUX('P', 15, AF9)>;
				slew-rate = "very-high-speed";
			};

		};
	};
};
